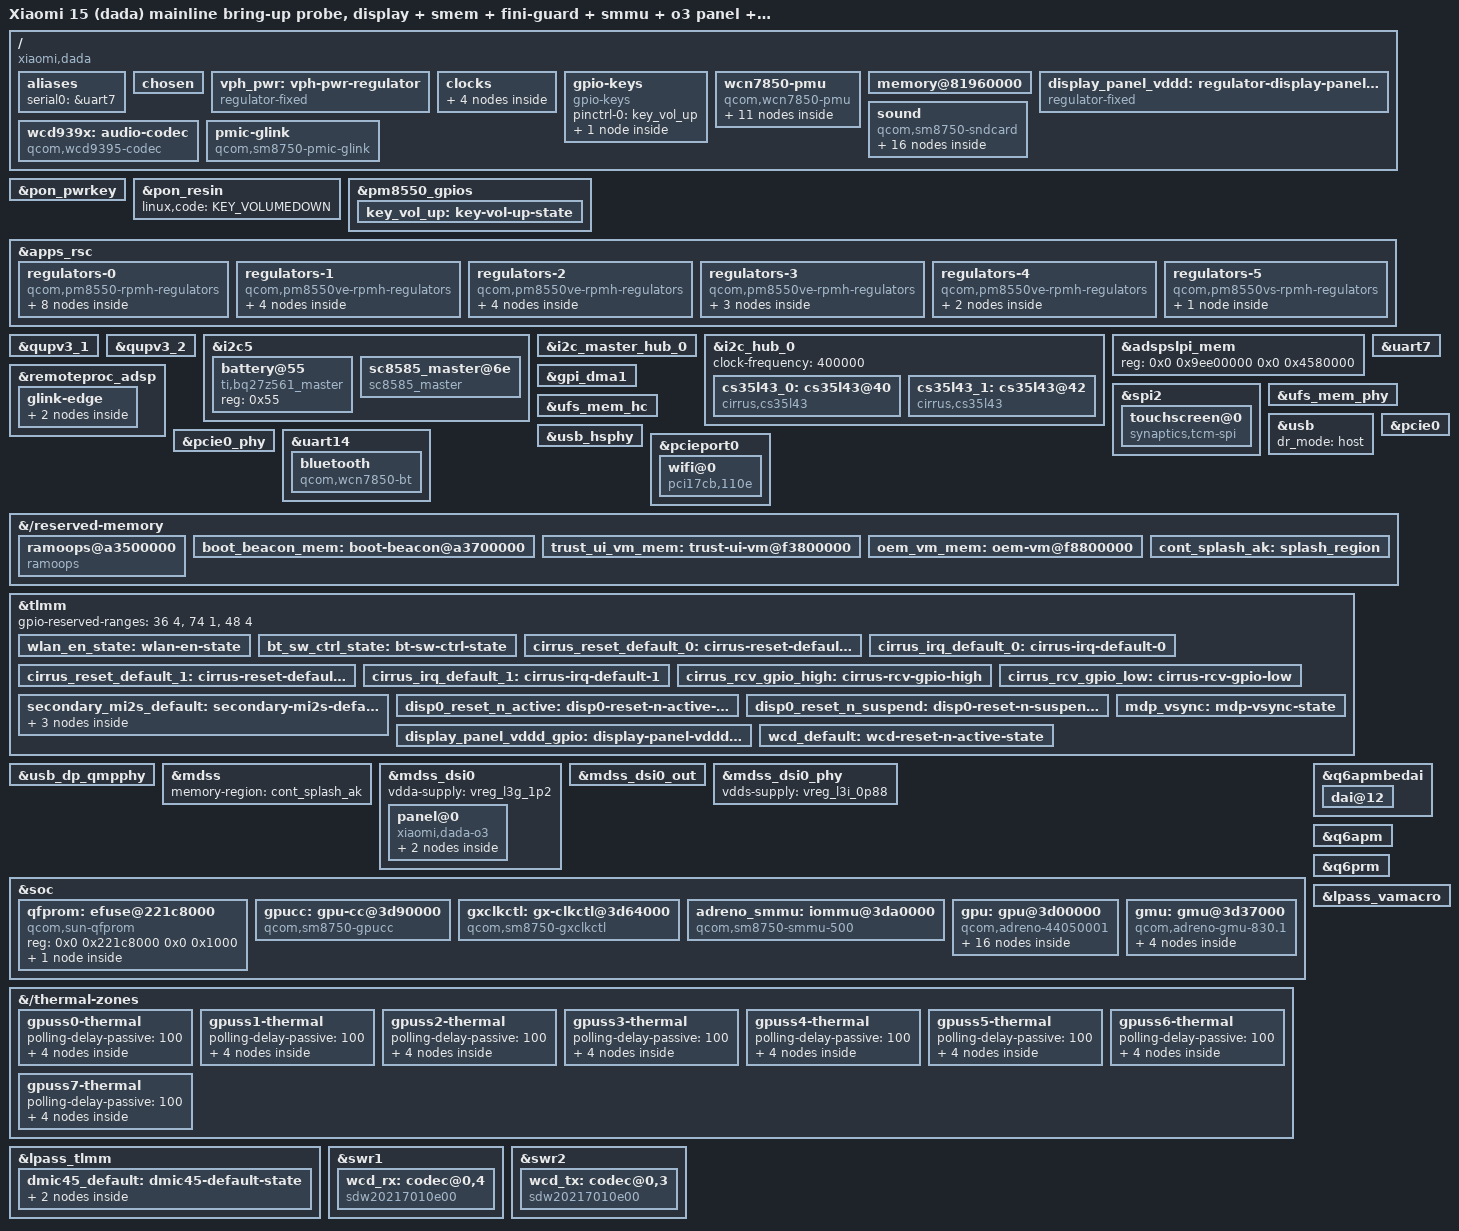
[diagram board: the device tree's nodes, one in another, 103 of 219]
// SPDX-License-Identifier: BSD-3-Clause
/*
 * Xiaomi 15 (dada) mainline bring-up board description -- CONSOLIDATED.
 *
 * This single file replaces the 66-file sm8750-xiaomi-dada-probe-*.dts include
 * chain (rounds m..cb) that had grown one thin override layer per bring-up
 * round. It was produced by work/kernel-source/scripts/merge-dts-chain.sh, which
 * walks the #include chain and inlines every board-level layer while KEEPING the
 * SoC and PMIC includes (sm8750.dtsi, the pm*.dtsi files, dt-bindings) as real
 * #include lines, so board-level picks of upstream DT changes still work.
 *
 * CORRECTNESS. The merge was verified to compile to a DTB that is BYTE-IDENTICAL
 * to the kernel's own build of the original chain, for rounds by, bz, ca and cb.
 * Nothing was dropped; the full round history lives in git (work/patches/round-*).
 *
 * WHY. The chain cost one DTS file + one Makefile dtb entry per round, so
 * `make dtbs` built 66 device trees for one board, and every new round meant
 * copying a file and wiring two more places. The rounds differed almost entirely
 * in /chosen bootargs; only ~10 of the 66 added real DT nodes.
 *
 * ROUND IDENTITY now lives in the `dada_probe=` cmdline token alone, not in the
 * filename. The current bootargs are the round-cb (SMP) set, with the probe tag
 * renamed builtin-dtb-cb -> builtin-dtb-mainline.
 *
 * HISTORY (oldest first): base board/PMIC/UFS/USB -> display bring-up probes
 * (m..aw: DPU/DSI enable, DSC, link config, readback, backlight, vendor table)
 * -> splash handover + SMMU direct-map (ax..bn) -> loopback rootfs -> pivot to
 * the rescue rootfs (bo) -> no-embedded-rootfs + dsi_host restored to BL (bp..bx)
 * -> persistent-rescue pivot + console prep (by) -> TSENS (bz) -> timing-robust
 * splash handover (ca) -> SMP, all 8 Oryon cores (cb).
 *
 * SECURITY: fastboot boot only, never flash; no partition written, erased or
 * made active; GPT never modified; read-only end to end except the one
 * pre-approved rescue-partition file, which the pivot rounds do not write
 * (round BO already seeded it). Per-run go-ahead required before any on-device
 * boot.
 *
 * Copyright (c) 2026 Xiaomi 15 mainline adaptation project
 */

/dts-v1/;

// SPDX-License-Identifier: BSD-3-Clause
/*
 * Xiaomi 15 (dada) initial mainline board description.
 *
 * This is deliberately a bring-up DTS.  Peripheral nodes are enabled only
 * after their vendor DT data has been mapped to mainline bindings.
 */


#include <dt-bindings/gpio/gpio.h>
#include <dt-bindings/input/input.h>
#include <dt-bindings/regulator/qcom,rpmh-regulator.h>
#include <dt-bindings/clock/qcom,sm8750-gpucc.h>
#include <dt-bindings/clock/qcom,kaanapali-gxclkctl.h>
#include <dt-bindings/sound/qcom,q6dsp-lpass-ports.h>
#include "sm8750.dtsi"
#include "pm8010.dtsi"
#include "pm8550.dtsi"
#define PMK8550VE_SID 8
#include "pm8550ve.dtsi"
#include "pmd8028.dtsi"
#include "pmih0108.dtsi"
#include "pmk8550.dtsi"
#include "pmr735d_a.dtsi"
#include "sm8750-pmics.dtsi"

/ {
	model = "Xiaomi 15";
	compatible = "xiaomi,dada", "qcom,sm8750";
	chassis-type = "handset";

	aliases {
		serial0 = &uart7;
	};

	chosen {
		stdout-path = "serial0:115200n8";
	};

	vph_pwr: vph-pwr-regulator {
		compatible = "regulator-fixed";

		regulator-name = "vph_pwr";
		regulator-min-microvolt = <3700000>;
		regulator-max-microvolt = <3700000>;

		regulator-always-on;
		regulator-boot-on;
	};

	clocks {
		xo_board: xo-board {
			compatible = "fixed-clock";
			clock-frequency = <76800000>;
			#clock-cells = <0>;
		};

		sleep_clk: sleep-clk {
			compatible = "fixed-clock";
			clock-frequency = <32000>;
			#clock-cells = <0>;
		};

		bi_tcxo_div2: bi-tcxo-div2-clk {
			compatible = "fixed-factor-clock";
			#clock-cells = <0>;

			clocks = <&rpmhcc RPMH_CXO_CLK>;
			clock-mult = <1>;
			clock-div = <2>;
		};

		bi_tcxo_ao_div2: bi-tcxo-ao-div2-clk {
			compatible = "fixed-factor-clock";
			#clock-cells = <0>;

			clocks = <&rpmhcc RPMH_CXO_CLK_A>;
			clock-mult = <1>;
			clock-div = <2>;
		};
	};
};

&pon_pwrkey {
	status = "okay";
};

&pon_resin {
	linux,code = <KEY_VOLUMEDOWN>;
	status = "okay";
};

/*
 * 音量加键不是 PON 键（电源键走 &pon_pwrkey，音量减走 &pon_resin）：
 * stock DT（android.dts fragment@3/@20）把它挂在 PM8550 PMIC GPIO6 上，
 * 由 gpio-keys 驱动处理 —— pinctrl input-enable + bias-pull-up +
 * power-source 1（1.8V），gpios active-low，linux,code=KEY_VOLUMEUP(0x73)，
 * gpio-key,wakeup，debounce 15ms。此前主线 DTS 缺这两个节点 ⇒ 音量加失效。
 */
&pm8550_gpios {
	key_vol_up: key-vol-up-state {
		pins = "gpio6";
		function = "normal";
		input-enable;
		bias-pull-up;
		power-source = <1>;
	};
};

/ {
	gpio-keys {
		compatible = "gpio-keys";

		pinctrl-names = "default";
		pinctrl-0 = <&key_vol_up>;

		vol_up {
			label = "volume_up";
			gpios = <&pm8550_gpios 6 GPIO_ACTIVE_LOW>;
			linux,input-type = <EV_KEY>;
			linux,code = <KEY_VOLUMEUP>;
			gpio-key,wakeup;
			debounce-interval = <15>;
		};
	};
};

&apps_rsc {
	regulators-0 {
		compatible = "qcom,pm8550-rpmh-regulators";

		vdd-bob1-supply = <&vph_pwr>;
		vdd-bob2-supply = <&vph_pwr>;
		vdd-l15-supply = <&vreg_s3g_1p8>;
		vdd-l17-supply = <&vreg_bob2>;

		qcom,pmic-id = "b";

		vreg_bob1: bob1 {
			regulator-name = "vreg_bob1";
			regulator-min-microvolt = <3008000>;
			regulator-max-microvolt = <4000000>;
			regulator-initial-mode = <RPMH_REGULATOR_MODE_HPM>;
		};

		vreg_bob2: bob2 {
			regulator-name = "vreg_bob2";
			regulator-min-microvolt = <2704000>;
			regulator-max-microvolt = <3008000>;
			regulator-initial-mode = <RPMH_REGULATOR_MODE_HPM>;
		};

		vreg_l17b_2p5: ldo17 {
			regulator-name = "vreg_l17b_2p5";
			regulator-min-microvolt = <2504000>;
			regulator-max-microvolt = <2504000>;
			regulator-initial-mode = <RPMH_REGULATOR_MODE_HPM>;
			regulator-allow-set-load;
			regulator-allowed-modes = <RPMH_REGULATOR_MODE_LPM
						   RPMH_REGULATOR_MODE_HPM>;
		};

		vreg_l15b_1p8: ldo15 {
			regulator-name = "vreg_l15b_1p8";
			regulator-min-microvolt = <1800000>;
			regulator-max-microvolt = <1800000>;
			regulator-initial-mode = <RPMH_REGULATOR_MODE_HPM>;
			regulator-allow-set-load;
			regulator-allowed-modes = <RPMH_REGULATOR_MODE_LPM
						   RPMH_REGULATOR_MODE_HPM>;
		};
	};

	regulators-1 {
		compatible = "qcom,pm8550ve-rpmh-regulators";

		vdd-l1-supply = <&vreg_s7i_1p2>;
		vdd-l2-supply = <&vreg_s1d_0p97>;
		vdd-l3-supply = <&vreg_s1d_0p97>;
		vdd-s1-supply = <&vph_pwr>;
		vdd-s3-supply = <&vph_pwr>;
		vdd-s4-supply = <&vph_pwr>;

		qcom,pmic-id = "d";

		vreg_s1d_0p97: smps1 {
			regulator-name = "vreg_s1d_0p97";
			regulator-min-microvolt = <880000>;
			regulator-max-microvolt = <1100000>;
			regulator-initial-mode = <RPMH_REGULATOR_MODE_HPM>;
		};

		vreg_s4d_0p85: smps4 {
			regulator-name = "vreg_s4d_0p85";
			regulator-min-microvolt = <500000>;
			regulator-max-microvolt = <1036000>;
			regulator-initial-mode = <RPMH_REGULATOR_MODE_HPM>;
		};

		vreg_l1d_1p2: ldo1 {
			regulator-name = "vreg_l1d_1p2";
			regulator-min-microvolt = <1200000>;
			regulator-max-microvolt = <1200000>;
			regulator-initial-mode = <RPMH_REGULATOR_MODE_HPM>;
			regulator-allow-set-load;
			regulator-allowed-modes = <RPMH_REGULATOR_MODE_LPM
						   RPMH_REGULATOR_MODE_HPM>;
		};
	};

	regulators-2 {
		compatible = "qcom,pm8550ve-rpmh-regulators";

		vdd-l1-supply = <&vreg_s1d_0p97>;
		vdd-l2-supply = <&vreg_s7i_1p2>;
		vdd-l3-supply = <&vreg_s3g_1p8>;
		vdd-s5-supply = <&vph_pwr>;

		qcom,pmic-id = "f";

		vreg_s5f_0p85: smps5 {
			regulator-name = "vreg_s5f_0p85";
			regulator-min-microvolt = <500000>;
			regulator-max-microvolt = <1000000>;
			regulator-initial-mode = <RPMH_REGULATOR_MODE_HPM>;
		};

		vreg_l1f_0p88: ldo1 {
			regulator-name = "vreg_l1f_0p88";
			regulator-min-microvolt = <880000>;
			regulator-max-microvolt = <880000>;
			regulator-initial-mode = <RPMH_REGULATOR_MODE_HPM>;
			regulator-allow-set-load;
			regulator-allowed-modes = <RPMH_REGULATOR_MODE_LPM
						   RPMH_REGULATOR_MODE_HPM>;
		};

		vreg_l2f_1p2: ldo2 {
			regulator-name = "vreg_l2f_1p2";
			regulator-min-microvolt = <1200000>;
			regulator-max-microvolt = <1200000>;
			regulator-initial-mode = <RPMH_REGULATOR_MODE_HPM>;
			regulator-allow-set-load;
			regulator-allowed-modes = <RPMH_REGULATOR_MODE_LPM
						   RPMH_REGULATOR_MODE_HPM>;
		};

		vreg_l3f_1p8: ldo3 {
			regulator-name = "vreg_l3f_1p8";
			regulator-min-microvolt = <1800000>;
			regulator-max-microvolt = <1800000>;
			regulator-initial-mode = <RPMH_REGULATOR_MODE_HPM>;
			regulator-allow-set-load;
			regulator-allowed-modes = <RPMH_REGULATOR_MODE_LPM
						   RPMH_REGULATOR_MODE_HPM>;
		};
	};

	regulators-3 {
		compatible = "qcom,pm8550ve-rpmh-regulators";

		vdd-l1-supply = <&vreg_s1d_0p97>;
		vdd-l2-supply = <&vreg_s3g_1p8>;
		vdd-l3-supply = <&vreg_s7i_1p2>;
		vdd-s1-supply = <&vph_pwr>;
		vdd-s3-supply = <&vph_pwr>;

		qcom,pmic-id = "g";

		vreg_s3g_1p8: smps3 {
			regulator-name = "vreg_s3g_1p8";
			regulator-min-microvolt = <1856000>;
			regulator-max-microvolt = <2000000>;
			regulator-initial-mode = <RPMH_REGULATOR_MODE_LPM>;
		};

		vreg_l3g_1p2: ldo3 {
			regulator-name = "vreg_l3g_1p2";
			regulator-min-microvolt = <1200000>;
			regulator-max-microvolt = <1256000>;
			regulator-initial-mode = <RPMH_REGULATOR_MODE_HPM>;
			regulator-allow-set-load;
			regulator-allowed-modes = <RPMH_REGULATOR_MODE_LPM
						   RPMH_REGULATOR_MODE_HPM>;
		};
	};

	regulators-4 {
		compatible = "qcom,pm8550ve-rpmh-regulators";

		vdd-l1-supply = <&vreg_s7i_1p2>;
		vdd-l2-supply = <&vreg_s7i_1p2>;
		vdd-l3-supply = <&vreg_s1d_0p97>;
		vdd-s7-supply = <&vph_pwr>;
		vdd-s8-supply = <&vph_pwr>;

		qcom,pmic-id = "i";

		vreg_s7i_1p2: smps7 {
			regulator-name = "vreg_s7i_1p2";
			regulator-min-microvolt = <1224000>;
			regulator-max-microvolt = <1340000>;
			regulator-initial-mode = <RPMH_REGULATOR_MODE_HPM>;
		};

		vreg_l2i_1p2: ldo2 {
			regulator-name = "vreg_l2i_1p2";
			regulator-min-microvolt = <1200000>;
			regulator-max-microvolt = <1200000>;
			regulator-initial-mode = <RPMH_REGULATOR_MODE_HPM>;
			regulator-allow-set-load;
			regulator-allowed-modes = <RPMH_REGULATOR_MODE_LPM
						   RPMH_REGULATOR_MODE_HPM>;
		};
	};

	regulators-5 {
		compatible = "qcom,pm8550vs-rpmh-regulators";

		vdd-l1-supply = <&vreg_s1d_0p97>;
		vdd-l2-supply = <&vreg_s7i_1p2>;
		vdd-s2-supply = <&vph_pwr>;
		vdd-s3-supply = <&vph_pwr>;
		vdd-s4-supply = <&vph_pwr>;

		qcom,pmic-id = "j";

		vreg_l1j_0p91: ldo1 {
			regulator-name = "vreg_l1j_0p91";
			regulator-min-microvolt = <880000>;
			regulator-max-microvolt = <920000>;
			regulator-initial-mode = <RPMH_REGULATOR_MODE_HPM>;
			regulator-allow-set-load;
			regulator-allowed-modes = <RPMH_REGULATOR_MODE_LPM
						   RPMH_REGULATOR_MODE_HPM>;
		};
	};
};

&qupv3_1 {
	status = "okay";
};

&qupv3_2 {
	status = "okay";
};

/*
 * Battery fuel gauge (2026-09-30).
 *
 * dada's battery data does NOT come from the ADSP: the stock DT keeps the
 * APSS-side pmic_glink battery clients disabled (/soc/qcom,pmic_glink/
 * qcom,battery_charger and mca,adsp_glink are both "disabled"), and once the
 * ADSP remoteproc is up the charger_pd service still answers every battmgr
 * property request with {0, 1, <property echoed>, 0} + 252 zero bytes.
 *
 * The real source is a TI bq27z561 fuel gauge on QUPv3_1 SE5 (i2c@a94000,
 * SDA gpio52 / SCL gpio53, address 0x55), which the stock DT keeps enabled
 * as ti,bq27z561_master.  Mainline's bq27xxx driver knows plain
 * ti,bq27z561: no unseal and no "master" mode is needed.  Verified on
 * hardware -- capacity 85 %, Discharging, 4.245 V, -361 mA, 38.9 C, 575
 * cycles, charge_full 4954 mAh / design 5400 mAh.  The design capacity comes
 * from the gauge's DCAP register, not from the stock DT's
 * bq,charge-full-design = 5300 mAh.
 *
 * Deliberately no monitored-battery child: bq27xxx_battery_settings() is its
 * only consumer and for BQ27Z561 (dm_regs == NULL) it bails out with "data
 * memory update not supported for chip", so it would only add a boot warning.
 */
&i2c5 {
	status = "okay";

	battery@55 {
		compatible = "ti,bq27z561_master";
		reg = <0x55>;
	};
};

/*
 * 扬声器：双 Cirrus CS35L43 挂在 I2C master hub 0（stock DTBO fragment@93
 * 的 target = qupv3_hub_i2c0 → 主线 i2c@980000，见 docs/audio-fix.md「硬件事实」2）。
 *
 * 两级都必须开：i2c_master_hub_0（父，geniqup@9c0000）在 sm8750.dtsi:1245
 * 与 i2c_hub_0 自身在 :1278 都是 status="disabled"。pad 沿用 dtsi 已有的
 * hub_i2c0_data_clk (gpio64/65)，无需另写 pinctrl。
 *
 * 风险：本文件上方注释记录过 i2c_hub_1 在传感器路线上 probe 死锁被放弃；
 * 功放走的是另一个 SE（hub 0），理论独立，但仍需上机验证。
 */
&i2c_master_hub_0 {
	status = "okay";
};

&i2c_hub_0 {
	status = "okay";

	/*
	 * dtsi 未给 clock-frequency，geni_i2c 会打 "Bus frequency not specified,
	 * default to 100kHz"（i2c-qcom-geni.c:1169-1173）。DSP 固件 .wmfw 里最大的
	 * PM_PACKED 区 19900 字节是单次 regmap_raw_write → 单条 I2C 事务，
	 * 100kHz 下约 1.79s，超过 geni_i2c 的 XFER_TIMEOUT=HZ（1s，i2c-qcom-geni.c:82）
	 * ⇒ cs_dsp.c:1676 "Failed to write 19900 bytes ...: -110"，固件加载中断。
	 * 400kHz 下约 0.45s；CS35L43 支持 fast mode。
	 */
	clock-frequency = <400000>;

	/* Bottom 主扬声器（stock phandle 0x26f，i2c-addr 0x28 → reg 0x40） */
	cs35l43_0: cs35l43@40 {
		compatible = "cirrus,cs35l43";
		reg = <0x40>;
		#sound-dai-cells = <0>;

		/*
		 * 一符三用：ASoC 的 DAPM widget / kcontrol 前缀（"B SPK"…），
		 * 以及 cs35l43_dsp_init 里 DSP 固件名的 part 前缀
		 * （"B-cs35l43" → wm_adsp.c:764 小写化 → cirrus/b-cs35l43-*.bin）。
		 * 取值必须与固件文件名的前缀一致，故用 "B"/"T" 而非 "Bottom"。
		 */
		sound-name-prefix = "B";

		interrupt-parent = <&tlmm>;
		interrupts = <84 0x2008>;
		reset-gpios = <&tlmm 107 GPIO_ACTIVE_HIGH>;

		pinctrl-names = "default";
		pinctrl-0 = <&cirrus_reset_default_0 &cirrus_irq_default_0>;

		/*
		 * 只写主线驱动 cs35l43_parse_pdata 实际读取的属性。
		 * stock 的 cirrus,vpbr-* / cirrus,bst-ipk-ma /
		 * cirrus,low-pwr-mode-standby 等主线一律不读，写了无用，
		 * 这里刻意省略（docs「架构结论」6）。
		 */
		cirrus,asp-sdout-hiz = <3>;
		cirrus,gpio2-src-sel = <4>;
	};

	/* Top 侧，兼作听筒（stock phandle 0x270，i2c-addr 0x2a → reg 0x42） */
	cs35l43_1: cs35l43@42 {
		compatible = "cirrus,cs35l43";
		reg = <0x42>;
		#sound-dai-cells = <0>;
		sound-name-prefix = "T";

		interrupt-parent = <&tlmm>;
		interrupts = <66 0x2008>;
		reset-gpios = <&tlmm 108 GPIO_ACTIVE_HIGH>;

		pinctrl-names = "default";
		pinctrl-0 = <&cirrus_reset_default_1 &cirrus_irq_default_1>;

		cirrus,asp-sdout-hiz = <3>;
		cirrus,gpio2-src-sel = <4>;
	};
};

/*
 * Sensor fix Phase 1: SSC path via ADSP remoteproc + FastRPC.
 *
 * The AP-side i2c-hub route (S1/A1/A2/B rounds) deadlocks in i2c_hub_1
 * probe and is abandoned; the same-SoC reference port (tb322fc Y700 Gen4,
 * Linux 7.2) validates accel/gyro/light through the SSC/ADSP instead.
 *
 * Stock dada DTB (extracted from vendor_boot_a.img) confirms the fastrpc
 * compute-cb iommus already match the upstream sm8750 base exactly
 * (cb@3 0x1003 0x80 + 0x1043 0x20; cb@7 0x1007 0x40 + 0x1067 0x00 +
 * 0x1087 0x00), so NO iommus override is needed -- unlike Y700, which
 * rewrites them. Only the PAS firmware names, enable, and stock's
 * nsessions on compute-cb@4 are added here.
 *
 * Firmware target on rootfs: /lib/firmware/qcom/sm8750/adsp.mdt (+ segments)
 * and adsp_dtb.mdt (+ segments), copied from the stock Android vendor image.
 *
 * Reserved-memory sizing: stock dada DTB reserves 0x4580000 for
 * adspslpi_region@9ee00000 while the mainline base only carves 0x3a80000.
 * The stock adsp.mdt is a relocatable ELF whose loadable segment span is
 * exactly 0x4580000 (0x9f300000..0xa3880000), so mainline's smaller window
 * fails qcom_mdt_load() with "segment outside memory range" (-22).  The
 * next real reserved node upstream is xbl-ramdump@b8000000, so growing the
 * region to the stock size collides with nothing.
 */
&adspslpi_mem {
	reg = <0x0 0x9ee00000 0x0 0x4580000>;
};

&remoteproc_adsp {
	firmware-name = "qcom/sm8750/adsp.mdt",
			"qcom/sm8750/adsp_dtb.mdt";
	status = "okay";

	glink-edge {
		fastrpc {
			compute-cb@4 {
				qcom,nsessions = <8>;
			};
		};
	};
};

&uart7 {
	status = "okay";
};

/*
 * Touch Round CM (SPI foundation). The touch IC -- Synaptics S3910P,
 * TouchComm over SPI, compatible "synaptics,tcm-spi" -- hangs off spi2
 * (QUPv3_1 SE2: irq TLMM gpio162 level-low+wakeup, reset gpio161, CS0
 * 15 MHz mode 0, per the stock runtime DT). The SoC dtsi carries the full
 * master node (pinctrl qup_spi2_data_clk/cs, GCC_QUPV3_WRAP1_S2_CLK,
 * interconnects, gpi_dma1 tx/rx channels) disabled, and its DMA engine
 * gpi_dma1 likewise; spi-geni probe defers forever if the SE comes up
 * GPI-only without it. Enable both here.
 * Inert while CONFIG_SPI_QCOM_GENI is off (no driver binds the node).
 *
 * Touch Round CN (TCM driver). The touch child node lands here, carrying
 * exactly the stock vendor properties (runtime.dts 24864-24940): irq gpio162
 * level-low, reset gpio161 active-high, 15 MHz SPI mode 0, avdd/iovdd named
 * supplies resolved to the pm8550 ("b" die) rails that own ldob16/ldob12 in
 * the stock DT (pm_humu_l16 = 3.0 V fixed avdd per the authoritative
 * runtime DT; pm_humu_l12 = 1.8 V iovdd), the panel geometry (1200x2670, tx 38 / rx 17) and the stock firmware image
 * name. Deliberately NOT ported: mi_tp,* arrays, qts/trusted-touch-*,
 * syna,qts_en, FOD arrays, xiaomi_touch (vendor framework glue).
 * The TCM driver reads its geometry from the IC app info; max-x/max-y/
 * tx-num/rx-num are kept for documentation parity with the stock DT.
 */
&gpi_dma1 {
	status = "okay";
};

&spi2 {
	status = "okay";

	touchscreen@0 {
		compatible = "synaptics,tcm-spi";
		reg = <0>;
		spi-max-frequency = <15000000>;
		synaptics,spi-mode = <0>;
		interrupt-parent = <&tlmm>;
		interrupts = <162 IRQ_TYPE_LEVEL_LOW>;
		synaptics,irq-gpio = <&tlmm 162 GPIO_ACTIVE_LOW>;
		synaptics,irq-on-state = <0>;
		synaptics,reset-gpio = <&tlmm 161 GPIO_ACTIVE_HIGH>;
		synaptics,reset-active-ms = <10>;
		synaptics,reset-delay-ms = <200>;
		synaptics,power-delay-ms = <50>;
		synaptics,avdd-name = "avdd";
		avdd-supply = <&vreg_l16b_3p0>;
		synaptics,iovdd-name = "iovdd";
		iovdd-supply = <&vreg_l12b_1p8>;
		synaptics,max-x = <1200>;
		synaptics,max-y = <2670>;
		synaptics,tx-num = <38>;
		synaptics,rx-num = <17>;
		synaptics,default-fw-image-name = "synaptics_spi_dada_00.img";
	};
};

/* Required for the first storage and USB bring-up pass. */
&ufs_mem_phy {
	vdda-phy-supply = <&vreg_l1j_0p91>;
	vdda-pll-supply = <&vreg_l3g_1p2>;

	status = "okay";
};

&ufs_mem_hc {
	reset-gpios = <&tlmm 215 GPIO_ACTIVE_LOW>;

	vcc-supply = <&vreg_l17b_2p5>;
	vcc-max-microamp = <1300000>;
	vccq-supply = <&vreg_l1d_1p2>;
	vccq-max-microamp = <1200000>;

	status = "okay";
};

&usb {
	dr_mode = "host";
	/delete-property/ usb-role-switch;
	status = "okay";
};

&usb_hsphy {
	status = "okay";
};

/* WiFi (WCN7850 "Peach") via PCIe. */
&pcie0 {
	vdda-supply = <&vreg_l1f_0p88>;
	pinctrl-0 = <&pcie0_default_state>;
	pinctrl-names = "default";
	status = "okay";
};

&pcie0_phy {
	vdda-phy-supply = <&vreg_l1f_0p88>;
	vdda-pll-supply = <&vreg_l3g_1p2>;
	status = "okay";
};

/ {
	wcn7850-pmu {
		compatible = "qcom,wcn7850-pmu";

		pinctrl-names = "default";
		pinctrl-0 = <&wlan_en_state>, <&bt_sw_ctrl_state>;

		wlan-enable-gpios = <&tlmm 16 GPIO_ACTIVE_HIGH>;
		bt-enable-gpios = <&pm8550ve_f_gpios 3 GPIO_ACTIVE_HIGH>;

		vdd-supply = <&vreg_s5f_0p85>;
		vddio-supply = <&vreg_l3f_1p8>;
		vddio1p2-supply = <&vreg_l2f_1p2>;
		vddaon-supply = <&vreg_s4d_0p85>;
		vdddig-supply = <&vreg_s5f_0p85>;
		vddrfa1p2-supply = <&vreg_s7i_1p2>;
		vddrfa1p8-supply = <&vreg_s3g_1p8>;

		clocks = <&rpmhcc RPMH_RF_CLK1>;

		regulators {
			vreg_pmu_rfa_cmn: ldo0 {
				regulator-name = "vreg_pmu_rfa_cmn";
			};

			vreg_pmu_aon_0p59: ldo1 {
				regulator-name = "vreg_pmu_aon_0p59";
			};

			vreg_pmu_wlcx_0p8: ldo2 {
				regulator-name = "vreg_pmu_wlcx_0p8";
			};

			vreg_pmu_wlmx_0p85: ldo3 {
				regulator-name = "vreg_pmu_wlmx_0p85";
			};

			vreg_pmu_btcmx_0p85: ldo4 {
				regulator-name = "vreg_pmu_btcmx_0p85";
			};

			vreg_pmu_rfa_0p8: ldo5 {
				regulator-name = "vreg_pmu_rfa_0p8";
			};

			vreg_pmu_rfa_1p2: ldo6 {
				regulator-name = "vreg_pmu_rfa_1p2";
			};

			vreg_pmu_rfa_1p8: ldo7 {
				regulator-name = "vreg_pmu_rfa_1p8";
			};

			vreg_pmu_pcie_0p9: ldo8 {
				regulator-name = "vreg_pmu_pcie_0p9";
			};

			vreg_pmu_pcie_1p8: ldo9 {
				regulator-name = "vreg_pmu_pcie_1p8";
			};
		};
	};
};

&uart14 {
	pinctrl-0 = <&qup_uart14_default>, <&qup_uart14_cts_rts>;

	status = "okay";

	/* WCN7880 (Peach, ganges) uses the WCN7850 UART protocol. */
	bluetooth {
		compatible = "qcom,wcn7850-bt";

		firmware-name = "gngbtnv20.bin", "gngbtfw20.mbn";
		/* Android-assigned public address 74:38:22:97:79:E5,
		 * stored little-endian in DT. */
		local-bd-address = [e5 79 97 22 38 74];

		vddrfacmn-supply = <&vreg_pmu_rfa_cmn>;
		vddaon-supply = <&vreg_pmu_aon_0p59>;
		vddwlcx-supply = <&vreg_pmu_wlcx_0p8>;
		vddwlmx-supply = <&vreg_pmu_wlmx_0p85>;
		vddrfa0p8-supply = <&vreg_pmu_rfa_0p8>;
		vddrfa1p2-supply = <&vreg_pmu_rfa_1p2>;
		vddrfa1p8-supply = <&vreg_pmu_rfa_1p8>;

		/* 主线 qca_get_baudrate_value() 无 8M case（default→115200 会
		 * 造成控制器留 115200、主机切 8M 的波特率错配），先按 MTP 用 3200000。 */
		max-speed = <3200000>;
	};
};

&pcieport0 {
	wake-gpios = <&tlmm 104 GPIO_ACTIVE_HIGH>;
	reset-gpios = <&tlmm 102 GPIO_ACTIVE_LOW>;

	wifi@0 {
		compatible = "pci17cb,110e";
		reg = <0x10000 0x0 0x0 0x0 0x0>;

		vddrfacmn-supply = <&vreg_pmu_rfa_cmn>;
		vddaon-supply = <&vreg_pmu_aon_0p59>;
		vddwlcx-supply = <&vreg_pmu_wlcx_0p8>;
		vddwlmx-supply = <&vreg_pmu_wlmx_0p85>;
		vddrfa0p8-supply = <&vreg_pmu_rfa_0p8>;
		vddrfa1p2-supply = <&vreg_pmu_rfa_1p2>;
		vddrfa1p8-supply = <&vreg_pmu_rfa_1p8>;
		vddpcie0p9-supply = <&vreg_pmu_pcie_0p9>;
		vddpcie1p8-supply = <&vreg_pmu_pcie_1p8>;
	};
};

/* The stock vendor DT reserves this area for crash/pstore records. */
&{/reserved-memory} {
	ramoops@a3500000 {
		compatible = "ramoops";
		reg = <0x0 0xa3500000 0x0 0x400000>;
		console-size = <0x200000>;
		pmsg-size = <0x200000>;
	};
};

/ {
	model = "Xiaomi 15 (dada) mainline bring-up probe";

	/*
	 * Verbatim from the ABL-populated /memory reg of the runtime device
	 * tree, sorted, with the single zero-length bank at 0xd8600000
	 * dropped. 15.12 GiB in 16 banks.
	 */
	memory@81960000 {
		device_type = "memory";
		reg = <0x00 0x81960000 0x00 0x000a0000>,
		      <0x00 0x81a40000 0x00 0x001c0000>,
		      <0x00 0x81cf4800 0x00 0x0000b800>,
		      <0x00 0x82460000 0x00 0x00040000>,
		      <0x00 0x82800000 0x00 0x02200000>,
		      <0x00 0x89d80000 0x00 0x01c80000>,
		      <0x00 0xa3380000 0x00 0x14c80000>,
		      <0x00 0xb8200000 0x00 0x1cc23000>,
		      <0x00 0xd5100000 0x00 0x02f00000>,
		      <0x00 0xe3720000 0x00 0x150e0000>,
		      <0x00 0xfc400000 0x00 0x03400000>,
		      <0x08 0x80000000 0x00 0x2f6fd000>,
		      <0x08 0xb0000000 0x00 0x05500000>,
		      <0x08 0xb5700000 0x00 0x01e00000>,
		      <0x08 0xc0000000 0x01 0x40000000>,
		      <0x0a 0x00000000 0x02 0x00000000>;
	};

	chosen {
		/*
		 * console=tty0 is intentional. The board has no accessible
		 * UART, and /chosen stdout-path would otherwise make the geni
		 * driver take over as the console; a console write that stalls
		 * on a port nobody is listening to would destroy the only
		 * evidence channel this probe has. Setting any console= on the
		 * command line makes of_console_check() ignore stdout-path,
		 * which is also what the stock kernel does.
		 *
		 * The pstore console does not need to be named here: it forces
		 * CON_ENABLED | CON_PRINTBUFFER | CON_ANYTIME at registration,
		 * so it is enabled anyway and replays the whole log buffer.
		 *
		 * clk/pd/regulator_ignore_unused keeps the late_initcall sync
		 * from switching off resources that firmware still owns.
		 *
		 * maxcpus=1 keeps secondary CPU bring-up out of the picture for
		 * the first probe.
		 *
		 * printk.devkmsg=on is required, not cosmetic. The default is
		 * ratelimit = 10 messages per 5 s per open fd, and round K lost
		 * exactly 6 of dada-init's lines to it (see
		 * evidence/probe-run-k-2026-09-06.md section 5.6).
		 *
		 * dada_probe= is only a self-identifying tag. Note it comes from
		 * HERE and not from the boot image header for this variant: the
		 * bootloader FDT is discarded, so /chosen in this blob is the
		 * only cmdline the kernel sees. Round K shipped with the stale
		 * "builtin-dtb-c" tag for that reason.
		 */
		bootargs = "console=tty0 ignore_loglevel nokaslr clk_ignore_unused pd_ignore_unused regulator_ignore_unused panic=5 printk.devkmsg=on rdinit=/dada-init dada_probe=builtin-dtb-gpu root=/dev/sda36 rw rootwait loglevel=4 systemd.show_status=yes ath12k.mac_addr=CE:76:4A:AB:26:35 root=/dev/sda36 rw rootwait loglevel=4 systemd.show_status=yes";
	};
};

&{/reserved-memory} {
	/*
	 * Two independent evidence channels, on two non-overlapping zones.
	 *
	 * Android declares ramoops at 0xa3500000 size 0x400000 with console-size
	 * and pmsg-size both 0x200000, and no record-size or ftrace-size. The
	 * mainline split order in ramoops_probe() is dmesg -> console -> ftrace
	 * -> pmsg, and dmesg and ftrace are both zero bytes here, so Android's
	 * console zone is 0xa3500000 and its pmsg zone is 0xa3700000.
	 *
	 * 0xa3700000 belongs to arm64_boot_beacon() alone. It is the reliable
	 * channel: it writes from inside setup_arch(), does explicit cache
	 * maintenance to the point of coherency, and never advances start, so its
	 * header satisfies start <= size at every instant. It reads back as
	 * /sys/fs/pstore/pmsg-ramoops-0.
	 *
	 * 0xa3500000 holds this kernel's own pstore_ram console zone, which only
	 * works if the kernel survives to driver init but then carries the whole
	 * replayed log. It reads back as /sys/fs/pstore/console-ramoops-0.
	 *
	 * These two must not share a zone. On 2026-09-05 both were pointed at
	 * 0xa3700000 and the resulting torn header cost the entire round: see
	 * plan section 13.13 and 13.14.
	 *
	 * CONFIG_ARM64_BOOT_BEACON_ADDR must stay 0xa3700000.
	 */
	/delete-node/ ramoops@a3500000;

	ramoops@a3500000 {
		compatible = "ramoops";
		reg = <0x00 0xa3500000 0x00 0x200000>;
		console-size = <0x200000>;
	};

	/*
	 * The beacon zone. Deliberately not a ramoops node: this kernel writes
	 * it by hand from setup_arch() onward and must not also have pstore_ram
	 * bookkeeping on it. It is reserved only to keep the page allocator out,
	 * which round D needs because its call sites now run past mm_core_init().
	 * Must match CONFIG_ARM64_BOOT_BEACON_ADDR / _SIZE.
	 */
	boot_beacon_mem: boot-beacon@a3700000 {
		reg = <0x00 0xa3700000 0x00 0x200000>;
		no-map;
	};

	/*
	 * Round K found "OF: reserved mem: OVERLAP DETECTED!" here. Upstream
	 * sm8750.dtsi and the dada runtime device tree disagree about both of
	 * these nodes, and this overlay had only followed the runtime tree for
	 * the first one:
	 *
	 *                   runtime (authoritative for dada)   sm8750.dtsi
	 *   trust-ui-vm     0xf3800000 + 0x5000000 (80M)       + 0x4400000 (68M)
	 *   oem-vm          0xf8800000 + 0x3800000 (56M)       0xf7c00000
	 *                                                      + 0x4c00000 (76M)
	 *
	 * Widening trust-ui-vm to the runtime size without also moving oem-vm
	 * left 0xf7c00000..0xf87fffff claimed twice. Both are no-map, so
	 * __rmem_check_for_overlap() only warned and round K was unharmed, but
	 * the probe tree is supposed to mirror the real memory map, so follow
	 * the runtime tree for both. Note the runtime node names are
	 * trust_ui_vm_region@/oem_vm_region@; keep the upstream node names so
	 * this stays a size/address correction and not a rename.
	 */
	trust_ui_vm_mem: trust-ui-vm@f3800000 {
		reg = <0x00 0xf3800000 0x00 0x5000000>;
		no-map;
	};

	/delete-node/ oem-vm@f7c00000;

	oem_vm_mem: oem-vm@f8800000 {
		reg = <0x00 0xf8800000 0x00 0x3800000>;
		no-map;
	};

	cont_splash_mem: cont-splash@fc800000 {
		reg = <0x00 0xfc800000 0x00 0x2b00000>;
		no-map;
	};
};

/ {
	model = "Xiaomi 15 (dada) mainline bring-up probe, pdc enabled";

	chosen {
		/*
		 * Byte-for-byte round L's command line with the tag changed. If
		 * this boot behaves differently from round L, CONFIG_QCOM_PDC=y
		 * has to be the only reason it can.
		 */
		bootargs = "console=tty0 ignore_loglevel nokaslr maxcpus=1 clk_ignore_unused pd_ignore_unused regulator_ignore_unused panic=5 printk.devkmsg=on rdinit=/dada-init dada_probe=builtin-dtb-gpu root=/dev/sda36 rw rootwait loglevel=4 systemd.show_status=yes ath12k.mac_addr=CE:76:4A:AB:26:35 root=/dev/sda36 rw rootwait loglevel=4 systemd.show_status=yes";
	};
};

/ {
	model = "Xiaomi 15 (dada) mainline bring-up probe, pdc + tlmm reserved";

	chosen {
		bootargs = "console=tty0 ignore_loglevel nokaslr maxcpus=1 clk_ignore_unused pd_ignore_unused regulator_ignore_unused panic=5 printk.devkmsg=on rdinit=/dada-init dada_probe=builtin-dtb-gpu root=/dev/sda36 rw rootwait loglevel=4 systemd.show_status=yes ath12k.mac_addr=CE:76:4A:AB:26:35 root=/dev/sda36 rw rootwait loglevel=4 systemd.show_status=yes";
	};
};

&tlmm {
	/*
	 * The single variable. See the header comment for why these three
	 * ranges and nothing else.
	 */
	gpio-reserved-ranges = <36 4>, <74 1>, <48 4>;

	wlan_en_state: wlan-en-state {
		pins = "gpio16";
		function = "gpio";
		drive-strength = <4>;
		bias-pull-down;
		output-low;
	};

	/* BT sw-ctrl (stock qcom,bt-sw-ctrl-gpio = tlmm 18), per sm8750-mtp. */
	bt_sw_ctrl_state: bt-sw-ctrl-state {
		pins = "gpio18";
		function = "gpio";
		bias-pull-down;
	};

	/*
	 * ── 音频：双 Cirrus CS35L43 + LPASS 第二接口（I2S/MI2S）──
	 * 见 docs/audio-fix.md「硬件事实」1/3。gpio 号全部来自 stock DTBO
	 * fragment@93 / :19244，且在本文件中无任何其它占用（已逐一核对）。
	 */

	/* amp@40 (Bottom, i2c 0x40)：reset=gpio107  irq=gpio84 */
	cirrus_reset_default_0: cirrus-reset-default-0 {
		pins = "gpio107";
		function = "gpio";
		drive-strength = <2>;
		bias-pull-up;
		output-high;
	};

	cirrus_irq_default_0: cirrus-irq-default-0 {
		pins = "gpio84";
		function = "gpio";
		drive-strength = <2>;
		bias-pull-up;
		input-enable;
	};

	/* amp@42 (Top, i2c 0x42)：reset=gpio108  irq=gpio66 */
	cirrus_reset_default_1: cirrus-reset-default-1 {
		pins = "gpio108";
		function = "gpio";
		drive-strength = <2>;
		bias-pull-up;
		output-high;
	};

	cirrus_irq_default_1: cirrus-irq-default-1 {
		pins = "gpio66";
		function = "gpio";
		drive-strength = <2>;
		bias-pull-up;
		input-enable;
	};

	/*
	 * amp@42 的听筒 rcv 脚（stock pinctrl-names 为 rcv_gpio_high/low，
	 * gpio152/gpio67）。方向与电平未知，第一阶段不挂到 amp 的 pinctrl-0，
	 * 仅预留 group 定义以免后续占用冲突。
	 */
	cirrus_rcv_gpio_high: cirrus-rcv-gpio-high {
		pins = "gpio152";
		function = "gpio";
		drive-strength = <2>;
		bias-pull-up;
		output-low;
	};

	cirrus_rcv_gpio_low: cirrus-rcv-gpio-low {
		pins = "gpio67";
		function = "gpio";
		drive-strength = <2>;
		bias-pull-up;
		output-low;
	};

	/*
	 * LPASS 第二接口的 pad（gpio121/123/124）。四个 function 各不相同，
	 * 故用嵌套 sub-group（同 lpass_tlmm 的 tx_swr_active 写法）。
	 * 逐字照抄已验证出声的 sm8750-lenovo-elden.dts:2091
	 * secondary_mi2s_default —— 不含 gpio122(din)，因为 I2S 播放单向，
	 * 且 CS35L43 的 IMON/VMON 走片内 ADC 不经外部 din。
	 * stock 的 aud_sleep state 也暂不建（elden 同样没有）。
	 */
	secondary_mi2s_default: secondary-mi2s-default-state {
		clock-pins {
			pins = "gpio121";
			function = "i2s1_sck";
			drive-strength = <8>;
			bias-disable;
		};
		word-select-pins {
			pins = "gpio123";
			function = "i2s1_ws";
			drive-strength = <8>;
			bias-disable;
		};
		data-pins {
			pins = "gpio124";
			function = "i2s1_data1";
			drive-strength = <8>;
			bias-disable;
		};
	};
};

/ {
	model = "Xiaomi 15 (dada) mainline bring-up probe, pdc + tlmm reserved + rpmh unblocked";

	chosen {
		/*
		 * Byte-for-byte the round P command line with the tag changed.
		 * If this boot behaves differently from round P, the deleted
		 * power-domains property has to be the only reason it can.
		 */
		bootargs = "console=tty0 ignore_loglevel nokaslr maxcpus=1 clk_ignore_unused pd_ignore_unused regulator_ignore_unused panic=5 printk.devkmsg=on rdinit=/dada-init dada_probe=builtin-dtb-gpu root=/dev/sda36 rw rootwait loglevel=4 systemd.show_status=yes ath12k.mac_addr=CE:76:4A:AB:26:35 root=/dev/sda36 rw rootwait loglevel=4 systemd.show_status=yes";
	};
};

&apps_rsc {
	/*
	 * The one line this file adds on top of round P. Round M's proven
	 * variable, verbatim from sm8750-xiaomi-dada-probe-m.dts.
	 *
	 * /delete-property/ and not a status change: apps_rsc must still probe,
	 * it must just stop waiting for a supplier that can never appear
	 * (/psci/power-domain-system never becomes a struct device because
	 * of_platform_default_populate() does not recurse into arm,psci-1.0
	 * and CONFIG_ARM_PSCI_CPUIDLE_DOMAIN is off in this kernel).
	 */
	/delete-property/ power-domains;
};

/ {
	model = "Xiaomi 15 (dada) mainline bring-up probe, pdc + tlmm + rpmh + g_serial";

	chosen {
		/*
		 * The Q command line plus console=ttyGS0,115200. ttynull
		 * stays as the early console (g_serial is not up until
		 * initcall time); once g_serial binds, the console switches.
		 * This is the standard two-stage console pattern for USB
		 * gadget consoles.
		 */
		bootargs = "console=tty0 ignore_loglevel nokaslr maxcpus=1 clk_ignore_unused pd_ignore_unused regulator_ignore_unused panic=5 printk.devkmsg=on rdinit=/dada-init dada_probe=builtin-dtb-gpu root=/dev/sda36 rw rootwait loglevel=4 systemd.show_status=yes ath12k.mac_addr=CE:76:4A:AB:26:35 root=/dev/sda36 rw rootwait loglevel=4 systemd.show_status=yes";
	};
};

/ {
	model = "Xiaomi 15 (dada) mainline bring-up probe, pdc + tlmm + rpmh + qmpphy + g_serial";

	chosen {
		/*
		 * Byte-for-byte the round R command line with the tag changed.
		 * If this boot behaves differently from round R, the enabled
		 * QMP phy has to be the only reason it can.
		 */
		bootargs = "console=tty0 ignore_loglevel nokaslr maxcpus=1 clk_ignore_unused pd_ignore_unused regulator_ignore_unused panic=5 printk.devkmsg=on rdinit=/dada-init dada_probe=builtin-dtb-gpu root=/dev/sda36 rw rootwait loglevel=4 systemd.show_status=yes ath12k.mac_addr=CE:76:4A:AB:26:35 root=/dev/sda36 rw rootwait loglevel=4 systemd.show_status=yes";
	};
};

&usb_dp_qmpphy {
	/* The single variable. See the header comment. */
	status = "okay";
};

/ {
	model = "Xiaomi 15 (dada) mainline bring-up probe, pdc + tlmm + rpmh + qmpphy + g_serial + ttyGS0 console";

	chosen {
		/*
		 * The S command line plus console=ttyGS0,115200. ttynull
		 * stays first (early console); ttyGS0 last (preferred).
		 * Everything else is byte-for-byte round S.
		 */
		bootargs = "console=tty0 ignore_loglevel nokaslr maxcpus=1 clk_ignore_unused pd_ignore_unused regulator_ignore_unused panic=5 printk.devkmsg=on rdinit=/dada-init dada_probe=builtin-dtb-gpu root=/dev/sda36 rw rootwait loglevel=4 systemd.show_status=yes ath12k.mac_addr=CE:76:4A:AB:26:35 root=/dev/sda36 rw rootwait loglevel=4 systemd.show_status=yes";
	};
};

/ {
	model = "Xiaomi 15 (dada) mainline bring-up probe, pdc + tlmm + rpmh + qmpphy + g_serial + interactive shell";

	chosen {
		/*
		 * Byte-for-byte the round T command line with the tag changed.
		 * The shell lives in the initramfs; the kernel and this DT
		 * are otherwise round T's.
		 */
		bootargs = "console=tty0 ignore_loglevel nokaslr maxcpus=1 clk_ignore_unused pd_ignore_unused regulator_ignore_unused panic=5 printk.devkmsg=on rdinit=/dada-init dada_probe=builtin-dtb-gpu root=/dev/sda36 rw rootwait loglevel=4 systemd.show_status=yes ath12k.mac_addr=CE:76:4A:AB:26:35 root=/dev/sda36 rw rootwait loglevel=4 systemd.show_status=yes";
	};
};

/ {
	model = "Xiaomi 15 (dada) mainline bring-up probe, pdc + tlmm + rpmh + qmpphy + g_serial + interactive shell + spmi-pmic mfd";

	chosen {
		/*
		 * Byte-for-byte the round T command line with the tag changed.
		 * The shell lives in the initramfs; the kernel and this DT
		 * are otherwise round T's.
		 */
		bootargs = "console=tty0 ignore_loglevel nokaslr maxcpus=1 clk_ignore_unused pd_ignore_unused regulator_ignore_unused panic=5 printk.devkmsg=on rdinit=/dada-init dada_probe=builtin-dtb-gpu root=/dev/sda36 rw rootwait loglevel=4 systemd.show_status=yes ath12k.mac_addr=CE:76:4A:AB:26:35 root=/dev/sda36 rw rootwait loglevel=4 systemd.show_status=yes";
	};
};

/ {
	model = "Xiaomi 15 (dada) mainline bring-up probe, pdc + tlmm + rpmh + qmpphy + g_serial + shell + spmi-pmic + pmic children";

	chosen {
		bootargs = "console=tty0 ignore_loglevel nokaslr maxcpus=1 clk_ignore_unused pd_ignore_unused regulator_ignore_unused panic=5 printk.devkmsg=on rdinit=/dada-init dada_probe=builtin-dtb-gpu root=/dev/sda36 rw rootwait loglevel=4 systemd.show_status=yes ath12k.mac_addr=CE:76:4A:AB:26:35 root=/dev/sda36 rw rootwait loglevel=4 systemd.show_status=yes";
	};
};

/ {
	model = "Xiaomi 15 (dada) mainline bring-up probe, pdc + tlmm + rpmh + qmpphy + g_serial + shell + pmic children + observation";

	chosen {
		bootargs = "console=tty0 ignore_loglevel nokaslr maxcpus=1 clk_ignore_unused pd_ignore_unused regulator_ignore_unused panic=5 printk.devkmsg=on rdinit=/dada-init dada_probe=builtin-dtb-gpu root=/dev/sda36 rw rootwait loglevel=4 systemd.show_status=yes ath12k.mac_addr=CE:76:4A:AB:26:35 root=/dev/sda36 rw rootwait loglevel=4 systemd.show_status=yes";
	};
};

/ {
	model = "Xiaomi 15 (dada) mainline bring-up probe, pdc + tlmm + rpmh + qmpphy + g_serial + shell + pmic children + iommu";

	chosen {
		bootargs = "console=tty0 ignore_loglevel nokaslr maxcpus=1 clk_ignore_unused pd_ignore_unused regulator_ignore_unused panic=5 printk.devkmsg=on rdinit=/dada-init dada_probe=builtin-dtb-gpu root=/dev/sda36 rw rootwait loglevel=4 systemd.show_status=yes ath12k.mac_addr=CE:76:4A:AB:26:35 root=/dev/sda36 rw rootwait loglevel=4 systemd.show_status=yes";
	};
};

&tlmm {
	disp0_reset_n_active: disp0-reset-n-active-state {
		pins = "gpio98";
		function = "gpio";
		drive-strength = <8>;
		bias-disable;
	};

	disp0_reset_n_suspend: disp0-reset-n-suspend-state {
		pins = "gpio98";
		function = "gpio";
		drive-strength = <2>;
		bias-pull-down;
	};

	mdp_vsync: mdp-vsync-state {
		pins = "gpio86";
		function = "mdp_vsync";
		drive-strength = <2>;
		bias-pull-down;
	};
};

&apps_rsc {
	regulators-0 {
		vreg_l11b_1p0: ldo11 {
			regulator-name = "vreg_l11b_1p0";
			regulator-min-microvolt = <1064000>;
			regulator-max-microvolt = <1292000>;
			regulator-initial-mode = <RPMH_REGULATOR_MODE_HPM>;
			regulator-allow-set-load;
			regulator-allowed-modes = <RPMH_REGULATOR_MODE_LPM
						   RPMH_REGULATOR_MODE_HPM>;
		};

		vreg_l12b_1p8: ldo12 {
			regulator-name = "vreg_l12b_1p8";
			regulator-min-microvolt = <1200000>;
			regulator-max-microvolt = <1800000>;
			regulator-initial-mode = <RPMH_REGULATOR_MODE_HPM>;
			regulator-allow-set-load;
			regulator-allowed-modes = <RPMH_REGULATOR_MODE_LPM
						   RPMH_REGULATOR_MODE_HPM>;
		};

		vreg_l13b_3p0: ldo13 {
			regulator-name = "vreg_l13b_3p0";
			regulator-min-microvolt = <3000000>;
			regulator-max-microvolt = <3000000>;
			regulator-initial-mode = <RPMH_REGULATOR_MODE_HPM>;
			regulator-allow-set-load;
			regulator-allowed-modes = <RPMH_REGULATOR_MODE_LPM
						   RPMH_REGULATOR_MODE_HPM>;
		};

		/* Touch Round CN: stock pm_humu_l16 = ldob16 (avdd, 3.0 V fixed;
		 * runtime.dts 29796-29805 min=max=init=0x2dc6c0 = 3000000 uV) */
		vreg_l16b_3p0: ldo16 {
			regulator-name = "vreg_l16b_3p0";
			regulator-min-microvolt = <3000000>;
			regulator-max-microvolt = <3000000>;
			regulator-initial-mode = <RPMH_REGULATOR_MODE_HPM>;
			regulator-allow-set-load;
			regulator-allowed-modes = <RPMH_REGULATOR_MODE_LPM
						   RPMH_REGULATOR_MODE_HPM>;
		};
	};

	regulators-1 {
		vreg_l3i_0p88: ldo3 {
			regulator-name = "vreg_l3i_0p88";
			regulator-min-microvolt = <880000>;
			regulator-max-microvolt = <880000>;
			regulator-initial-mode = <RPMH_REGULATOR_MODE_HPM>;
		};
	};
};

&mdss {
	status = "okay";
};

&mdss_dsi0 {
	vdda-supply = <&vreg_l3g_1p2>;

	status = "okay";

	panel@0 {
		compatible = "novatek,nt37801";
		reg = <0>;

		reset-gpios = <&tlmm 98 GPIO_ACTIVE_LOW>;

		vddio-supply = <&vreg_l12b_1p8>;
		vci-supply = <&vreg_l13b_3p0>;
		vdd-supply = <&vreg_l11b_1p0>;

		pinctrl-0 = <&disp0_reset_n_active>, <&mdp_vsync>;
		pinctrl-1 = <&disp0_reset_n_suspend>, <&mdp_vsync>;
		pinctrl-names = "default", "sleep";

		port {
			panel0_in: endpoint {
				remote-endpoint = <&mdss_dsi0_out>;
			};
		};
	};
};

&mdss_dsi0_out {
	remote-endpoint = <&panel0_in>;
	data-lanes = <0 1 2 3>;
};

&mdss_dsi0_phy {
	vdds-supply = <&vreg_l3i_0p88>;

	status = "okay";
};

/ {
	model = "Xiaomi 15 (dada) mainline bring-up probe, pdc + tlmm + rpmh + qmpphy + g_serial + shell + pmic children + iommu + drm-msm nt37801";

	chosen {
		bootargs = "console=tty0 ignore_loglevel nokaslr maxcpus=1 clk_ignore_unused pd_ignore_unused regulator_ignore_unused panic=5 printk.devkmsg=on rdinit=/dada-init dada_probe=builtin-dtb-gpu root=/dev/sda36 rw rootwait loglevel=4 systemd.show_status=yes ath12k.mac_addr=CE:76:4A:AB:26:35 root=/dev/sda36 rw rootwait loglevel=4 systemd.show_status=yes";
	};
};

/ {
	model = "Xiaomi 15 (dada) mainline bring-up probe, display + smem";

	chosen {
		bootargs = "console=tty0 ignore_loglevel nokaslr maxcpus=1 clk_ignore_unused pd_ignore_unused regulator_ignore_unused panic=5 printk.devkmsg=on rdinit=/dada-init dada_probe=builtin-dtb-gpu root=/dev/sda36 rw rootwait loglevel=4 systemd.show_status=yes ath12k.mac_addr=CE:76:4A:AB:26:35 root=/dev/sda36 rw rootwait loglevel=4 systemd.show_status=yes";
	};
};

/ {
	model = "Xiaomi 15 (dada) mainline bring-up probe, display + smem + dpu-fini-guard";

	chosen {
		bootargs = "console=tty0 ignore_loglevel nokaslr maxcpus=1 clk_ignore_unused pd_ignore_unused regulator_ignore_unused panic=5 printk.devkmsg=on rdinit=/dada-init dada_probe=builtin-dtb-gpu root=/dev/sda36 rw rootwait loglevel=4 systemd.show_status=yes ath12k.mac_addr=CE:76:4A:AB:26:35 root=/dev/sda36 rw rootwait loglevel=4 systemd.show_status=yes";
	};
};

/ {
	model = "Xiaomi 15 (dada) mainline bring-up probe, display + smem + fini-guard + log-tail";

	chosen {
		bootargs = "console=tty0 ignore_loglevel nokaslr maxcpus=1 clk_ignore_unused pd_ignore_unused regulator_ignore_unused panic=5 printk.devkmsg=on rdinit=/dada-init dada_probe=builtin-dtb-gpu root=/dev/sda36 rw rootwait loglevel=4 systemd.show_status=yes ath12k.mac_addr=CE:76:4A:AB:26:35 root=/dev/sda36 rw rootwait loglevel=4 systemd.show_status=yes";
	};
};

/ {
	model = "Xiaomi 15 (dada) mainline bring-up probe, display + smem + fini-guard + smmu";

	chosen {
		bootargs = "console=tty0 ignore_loglevel nokaslr maxcpus=1 clk_ignore_unused pd_ignore_unused regulator_ignore_unused panic=5 printk.devkmsg=on rdinit=/dada-init dada_probe=builtin-dtb-gpu root=/dev/sda36 rw rootwait loglevel=4 systemd.show_status=yes ath12k.mac_addr=CE:76:4A:AB:26:35 root=/dev/sda36 rw rootwait loglevel=4 systemd.show_status=yes";
	};
};

/ {
	model = "Xiaomi 15 (dada) mainline bring-up probe, display + smem + fini-guard + smmu + o3 panel";

	chosen {
		bootargs = "console=tty0 ignore_loglevel nokaslr maxcpus=1 clk_ignore_unused pd_ignore_unused regulator_ignore_unused panic=5 printk.devkmsg=on rdinit=/dada-init dada_probe=builtin-dtb-gpu root=/dev/sda36 rw rootwait loglevel=4 systemd.show_status=yes ath12k.mac_addr=CE:76:4A:AB:26:35 root=/dev/sda36 rw rootwait loglevel=4 systemd.show_status=yes";
	};

	display_panel_vddd: regulator-display-panel-vddd {
		compatible = "regulator-fixed";
		regulator-name = "display_panel_vddd";
		regulator-min-microvolt = <1200000>;
		regulator-max-microvolt = <1200000>;
		gpio = <&tlmm 120 GPIO_ACTIVE_HIGH>;
		enable-active-high;
		regulator-boot-on;
		pinctrl-names = "default";
		pinctrl-0 = <&display_panel_vddd_gpio>;
	};
};

&tlmm {
	display_panel_vddd_gpio: display-panel-vddd-gpio-state {
		pins = "gpio120";
		function = "gpio";
		drive-strength = <2>;
		bias-disable;
	};
};

&apps_rsc {
	regulators-3 {
		/* The g-side LDO the vendor feeds the panel's vddio from
		 * (regulator-pm-v8g-l2 in the runtime tree); values from
		 * upstream sm8750-mtp.dts, whose vdd-l2 parent (s3g) the
		 * regulators-3 block already declares. */
		vreg_l2g_1p8: ldo2 {
			regulator-name = "vreg_l2g_1p8";
			regulator-min-microvolt = <1200000>;
			regulator-max-microvolt = <1860000>;
			regulator-initial-mode = <RPMH_REGULATOR_MODE_HPM>;
			regulator-allow-set-load;
			regulator-allowed-modes = <RPMH_REGULATOR_MODE_LPM
						   RPMH_REGULATOR_MODE_HPM>;
		};
	};
};

&mdss_dsi0 {
	panel@0 {
		compatible = "xiaomi,dada-o3";

		vddio-supply = <&vreg_l2g_1p8>;
		vci-supply = <&vreg_l13b_3p0>;
		vddd-supply = <&display_panel_vddd>;
		/delete-property/ vdd-supply;
	};
};

/ {
	model = "Xiaomi 15 (dada) mainline bring-up probe, display + smem + fini-guard + smmu + o3 panel + readback";

	chosen {
		bootargs = "console=tty0 ignore_loglevel nokaslr maxcpus=1 clk_ignore_unused pd_ignore_unused regulator_ignore_unused panic=5 printk.devkmsg=on rdinit=/dada-init dada_probe=builtin-dtb-gpu root=/dev/sda36 rw rootwait loglevel=4 systemd.show_status=yes ath12k.mac_addr=CE:76:4A:AB:26:35 root=/dev/sda36 rw rootwait loglevel=4 systemd.show_status=yes";
	};
};

/ {
	model = "Xiaomi 15 (dada) mainline bring-up probe, display + smem + fini-guard + smmu + o3 panel + 1 read";

	chosen {
		bootargs = "console=tty0 ignore_loglevel nokaslr maxcpus=1 clk_ignore_unused pd_ignore_unused regulator_ignore_unused panic=5 printk.devkmsg=on rdinit=/dada-init dada_probe=builtin-dtb-gpu root=/dev/sda36 rw rootwait loglevel=4 systemd.show_status=yes ath12k.mac_addr=CE:76:4A:AB:26:35 root=/dev/sda36 rw rootwait loglevel=4 systemd.show_status=yes";
	};
};

/ {
	model = "Xiaomi 15 (dada) mainline bring-up probe, display + smem + fini-guard + smmu + o3 panel + read sweep";

	chosen {
		bootargs = "console=tty0 ignore_loglevel nokaslr maxcpus=1 clk_ignore_unused pd_ignore_unused regulator_ignore_unused panic=5 printk.devkmsg=on rdinit=/dada-init dada_probe=builtin-dtb-gpu root=/dev/sda36 rw rootwait loglevel=4 systemd.show_status=yes ath12k.mac_addr=CE:76:4A:AB:26:35 root=/dev/sda36 rw rootwait loglevel=4 systemd.show_status=yes";
	};
};

/ {
	model = "Xiaomi 15 (dada) mainline bring-up probe, display + smem + fini-guard + smmu + o3 panel + bl readback";

	chosen {
		bootargs = "console=tty0 ignore_loglevel nokaslr maxcpus=1 clk_ignore_unused pd_ignore_unused regulator_ignore_unused panic=5 printk.devkmsg=on rdinit=/dada-init dada_probe=builtin-dtb-gpu root=/dev/sda36 rw rootwait loglevel=4 systemd.show_status=yes ath12k.mac_addr=CE:76:4A:AB:26:35 root=/dev/sda36 rw rootwait loglevel=4 systemd.show_status=yes";
	};
};

/ {
	model = "Xiaomi 15 (dada) mainline bring-up probe, display + smem + fini-guard + smmu + o3 panel + bl readback + dsc link cfg";

	chosen {
		bootargs = "console=tty0 ignore_loglevel nokaslr maxcpus=1 clk_ignore_unused pd_ignore_unused regulator_ignore_unused panic=5 printk.devkmsg=on rdinit=/dada-init dada_probe=builtin-dtb-gpu root=/dev/sda36 rw rootwait loglevel=4 systemd.show_status=yes ath12k.mac_addr=CE:76:4A:AB:26:35 root=/dev/sda36 rw rootwait loglevel=4 systemd.show_status=yes";
	};
};

/ {
	model = "Xiaomi 15 (dada) mainline bring-up probe, display + smem + fini-guard + smmu + o3 panel + bl readback + dsc link cfg + splash handover";

	chosen {
		bootargs = "console=tty0 ignore_loglevel nokaslr maxcpus=1 clk_ignore_unused pd_ignore_unused regulator_ignore_unused panic=5 printk.devkmsg=on rdinit=/dada-init dada_probe=builtin-dtb-gpu root=/dev/sda36 rw rootwait loglevel=4 systemd.show_status=yes ath12k.mac_addr=CE:76:4A:AB:26:35 root=/dev/sda36 rw rootwait loglevel=4 systemd.show_status=yes";
	};
};

/* The round-AK variable: keep the ABL splash translations alive across
 * the kernel's SMMU takeover so the handoff cannot fault-terminate a
 * stalled MDSS fetch and wedge the bus. Identity mapping: the iova
 * equals the physical address of the region. The plain cont-splash node
 * from the base probe tree is deleted and re-added with the
 * iommu-addresses property -- same address and size, one node, no
 * overlap.
 *
 * NODE NAME: must be exactly "splash_region", with NO unit address.
 * Qualcomm's ABL looks the region up by the literal path
 * /reserved-memory/splash_region; if it cannot find it, it tears the
 * display down instead of handing a live framebuffer to the kernel.
 * This is the form the device's own stock DT uses -- see
 * device-tree/runtime.dts:703 (node "splash_region", no unit address,
 * label = "cont_splash_region", same reg) and the stock dtbo overlay.
 * Upstream carries the same warning on two Samsung boards, e.g.
 * arch/arm64/boot/dts/qcom/sm8450-samsung-r0q.dts:43 ("The bootloader
 * will only keep display hardware enabled if this memory region is
 * named exactly 'splash_region'"). A reserved-memory child with no
 * unit address is a legal form -- dtc builds this clean, no
 * unit_address_vs_reg warning. */
&{/reserved-memory} {
	/delete-node/ cont-splash@fc800000;

	cont_splash_ak: splash_region {
		reg = <0x0 0xfc800000 0x0 0x2b00000>;
		iommu-addresses = <&mdss 0x0 0xfc800000 0x0 0x2b00000>;
		label = "cont_splash_region";
		no-map;
	};
};

&mdss {
	memory-region = <&cont_splash_ak>;
};

/ {
	model = "Xiaomi 15 (dada) mainline bring-up probe, display + smem + fini-guard + smmu + o3 panel + bl readback + dsc link cfg + splash handover + vendor dsc table";

	chosen {
		bootargs = "console=tty0 ignore_loglevel nokaslr maxcpus=1 clk_ignore_unused pd_ignore_unused regulator_ignore_unused panic=5 printk.devkmsg=on rdinit=/dada-init dada_probe=builtin-dtb-gpu root=/dev/sda36 rw rootwait loglevel=4 systemd.show_status=yes ath12k.mac_addr=CE:76:4A:AB:26:35 root=/dev/sda36 rw rootwait loglevel=4 systemd.show_status=yes";
	};
};

/ {
	model = "Xiaomi 15 (dada) mainline bring-up probe, display + smem + fini-guard + smmu + o3 panel + bl readback + dsc link cfg + splash handover + vendor dsc table + vendor dsc rc config + raw blob pps bit4";

	chosen {
		bootargs = "console=tty0 ignore_loglevel nokaslr maxcpus=1 clk_ignore_unused pd_ignore_unused regulator_ignore_unused panic=5 printk.devkmsg=on rdinit=/dada-init dada_probe=builtin-dtb-gpu root=/dev/sda36 rw rootwait loglevel=4 systemd.show_status=yes ath12k.mac_addr=CE:76:4A:AB:26:35 root=/dev/sda36 rw rootwait loglevel=4 systemd.show_status=yes";
	};
};

/ {
	model = "Xiaomi 15 (dada) mainline bring-up probe, display + smem + fini-guard + smmu + o3 panel + bl readback + dsc link cfg + splash handover + vendor dsc table + vendor dsc rc config + raw blob pps bit4 + n422 clear";

	chosen {
		bootargs = "console=tty0 ignore_loglevel nokaslr maxcpus=1 clk_ignore_unused pd_ignore_unused regulator_ignore_unused panic=5 printk.devkmsg=on rdinit=/dada-init dada_probe=builtin-dtb-gpu root=/dev/sda36 rw rootwait loglevel=4 systemd.show_status=yes ath12k.mac_addr=CE:76:4A:AB:26:35 root=/dev/sda36 rw rootwait loglevel=4 systemd.show_status=yes";
	};
};

/ {
	model = "Xiaomi 15 (dada) mainline bring-up probe, display + smem + fini-guard + smmu + o3 panel + bl readback + dsc link cfg + splash handover + vendor dsc table + vendor dsc rc config + raw blob pps bit4 + n422 clear + vendor initial lines";

	chosen {
		bootargs = "console=tty0 ignore_loglevel nokaslr maxcpus=1 clk_ignore_unused pd_ignore_unused regulator_ignore_unused panic=5 printk.devkmsg=on rdinit=/dada-init dada_probe=builtin-dtb-gpu root=/dev/sda36 rw rootwait loglevel=4 systemd.show_status=yes ath12k.mac_addr=CE:76:4A:AB:26:35 root=/dev/sda36 rw rootwait loglevel=4 systemd.show_status=yes";
	};
};

/ {
	model = "Xiaomi 15 (dada) mainline bring-up probe, display + smem + fini-guard + smmu + o3 panel + bl readback + dsc link cfg + splash handover + vendor dsc table + vendor dsc rc config + raw blob pps bit4 + n422 clear + vendor initial lines + stay + bpp revert";

	chosen {
		bootargs = "console=tty0 ignore_loglevel nokaslr maxcpus=1 clk_ignore_unused pd_ignore_unused regulator_ignore_unused panic=5 printk.devkmsg=on rdinit=/dada-init dada_probe=builtin-dtb-gpu root=/dev/sda36 rw rootwait loglevel=4 systemd.show_status=yes ath12k.mac_addr=CE:76:4A:AB:26:35 root=/dev/sda36 rw rootwait loglevel=4 systemd.show_status=yes dada_stay";
	};
};

/ {
	model = "Xiaomi 15 (dada) mainline bring-up probe, display + smem + fini-guard + smmu + o3 panel + bl readback + dsc link cfg + splash handover + vendor dsc table + vendor dsc rc config + raw blob pps bit4 + n422 clear + vendor initial lines + stay + content + dsc bpp 128/128 + vt quiesce + paced log + no test pattern + u_serial console fix + splash rename";

	chosen {
		bootargs = "console=tty0 ignore_loglevel nokaslr maxcpus=1 clk_ignore_unused pd_ignore_unused regulator_ignore_unused panic=5 printk.devkmsg=on rdinit=/dada-init dada_probe=builtin-dtb-gpu root=/dev/sda36 rw rootwait loglevel=4 systemd.show_status=yes ath12k.mac_addr=CE:76:4A:AB:26:35 root=/dev/sda36 rw rootwait loglevel=4 systemd.show_status=yes dada_stay panel_xiaomi_dada_o3.pps_bpp=128 panel_xiaomi_dada_o3.enc_bpp=128 panel_xiaomi_dada_o3.dsc_native_422=1 panel_xiaomi_dada_o3.dsc_cvt_rgb=0";
	};
};

/ {
	model = "Xiaomi 15 (dada) mainline bring-up probe, display + smem + fini-guard + smmu + o3 panel + bl readback + dsc link cfg + splash handover + vendor dsc table + vendor dsc rc config + raw blob pps bit4 + n422 clear + vendor initial lines + stay + content + dsc bpp 128/128 + vt quiesce + paced log + no test pattern + u_serial console fix + splash rename + sm8750 mdss identity";

	chosen {
		bootargs = "console=tty0 ignore_loglevel nokaslr maxcpus=1 clk_ignore_unused pd_ignore_unused regulator_ignore_unused panic=5 printk.devkmsg=on rdinit=/dada-init dada_probe=builtin-dtb-gpu root=/dev/sda36 rw rootwait loglevel=4 systemd.show_status=yes ath12k.mac_addr=CE:76:4A:AB:26:35 root=/dev/sda36 rw rootwait loglevel=4 systemd.show_status=yes dada_stay panel_xiaomi_dada_o3.pps_bpp=128 panel_xiaomi_dada_o3.enc_bpp=128 panel_xiaomi_dada_o3.dsc_native_422=1 panel_xiaomi_dada_o3.dsc_cvt_rgb=0";
	};
};

/ {
	model = "Xiaomi 15 (dada) mainline bring-up probe, display + smem + fini-guard + smmu + o3 panel + bl readback + dsc link cfg + splash handover + vendor dsc table + vendor dsc rc config + raw blob pps bit4 + n422 clear + vendor initial lines + stay + content + dsc bpp 128/128 + vt quiesce + paced log + no test pattern + u_serial console fix + splash rename + sm8750 mdss identity + ufs read + ro mount";

	chosen {
		bootargs = "console=tty0 ignore_loglevel nokaslr maxcpus=1 clk_ignore_unused pd_ignore_unused regulator_ignore_unused panic=5 printk.devkmsg=on rdinit=/dada-init dada_probe=builtin-dtb-gpu root=/dev/sda36 rw rootwait loglevel=4 systemd.show_status=yes ath12k.mac_addr=CE:76:4A:AB:26:35 root=/dev/sda36 rw rootwait loglevel=4 systemd.show_status=yes dada_stay panel_xiaomi_dada_o3.pps_bpp=128 panel_xiaomi_dada_o3.enc_bpp=128 panel_xiaomi_dada_o3.dsc_native_422=1 panel_xiaomi_dada_o3.dsc_cvt_rgb=0";
	};
};

/ {
	model = "Xiaomi 15 (dada) mainline bring-up probe, display + smem + fini-guard + smmu + o3 panel + bl readback + dsc link cfg + splash handover + vendor dsc table + vendor dsc rc config + raw blob pps bit4 + n422 clear + vendor initial lines + stay + content + dsc bpp 128/128 + vt quiesce + paced log + no test pattern + u_serial console fix + splash rename + sm8750 mdss identity + ufs read + ro mount + sb magic";

	chosen {
		bootargs = "console=tty0 ignore_loglevel nokaslr maxcpus=1 clk_ignore_unused pd_ignore_unused regulator_ignore_unused panic=5 printk.devkmsg=on rdinit=/dada-init dada_probe=builtin-dtb-gpu root=/dev/sda36 rw rootwait loglevel=4 systemd.show_status=yes ath12k.mac_addr=CE:76:4A:AB:26:35 root=/dev/sda36 rw rootwait loglevel=4 systemd.show_status=yes dada_stay panel_xiaomi_dada_o3.pps_bpp=128 panel_xiaomi_dada_o3.enc_bpp=128 panel_xiaomi_dada_o3.dsc_native_422=1 panel_xiaomi_dada_o3.dsc_cvt_rgb=0";
	};
};

/ {
	model = "Xiaomi 15 (dada) mainline bring-up probe, display + smem + fini-guard + smmu + o3 panel + bl readback + dsc link cfg + splash handover + vendor dsc table + vendor dsc rc config + raw blob pps bit4 + n422 clear + vendor initial lines + stay + content + dsc bpp 128/128 + vt quiesce + paced log + no test pattern + u_serial console fix + splash rename + sm8750 mdss identity + ufs read + ro mount + sb magic + usb net + backlight adjust + ms lun removable";

	chosen {
		bootargs = "console=tty0 ignore_loglevel nokaslr maxcpus=1 clk_ignore_unused pd_ignore_unused regulator_ignore_unused panic=5 printk.devkmsg=on rdinit=/dada-init dada_probe=builtin-dtb-gpu root=/dev/sda36 rw rootwait loglevel=4 systemd.show_status=yes ath12k.mac_addr=CE:76:4A:AB:26:35 root=/dev/sda36 rw rootwait loglevel=4 systemd.show_status=yes dada_stay g_multi.removable=1 panel_xiaomi_dada_o3.pps_bpp=128 panel_xiaomi_dada_o3.enc_bpp=128 panel_xiaomi_dada_o3.dsc_native_422=1 panel_xiaomi_dada_o3.dsc_cvt_rgb=0";
	};
};

/ {
	model = "Xiaomi 15 (dada) mainline bring-up probe, display + smem + fini-guard + smmu + o3 panel + bl readback + dsc link cfg + splash handover + vendor dsc table + vendor dsc rc config + raw blob pps bit4 + n422 clear + vendor initial lines + stay + content + dsc bpp 128/128 + vt quiesce + paced log + no test pattern + u_serial console fix + splash rename + sm8750 mdss identity + ufs read + ro mount + sb magic + usb net + backlight adjust + ms lun removable + loopback rootfs";

	chosen {
		bootargs = "console=tty0 ignore_loglevel nokaslr maxcpus=1 clk_ignore_unused pd_ignore_unused regulator_ignore_unused panic=5 printk.devkmsg=on rdinit=/dada-init dada_probe=builtin-dtb-gpu root=/dev/sda36 rw rootwait loglevel=4 systemd.show_status=yes ath12k.mac_addr=CE:76:4A:AB:26:35 root=/dev/sda36 rw rootwait loglevel=4 systemd.show_status=yes dada_stay panel_xiaomi_dada_o3.pps_bpp=128 panel_xiaomi_dada_o3.enc_bpp=128 panel_xiaomi_dada_o3.dsc_native_422=1 panel_xiaomi_dada_o3.dsc_cvt_rgb=0";
	};
};

/ {
	model = "Xiaomi 15 (dada) mainline bring-up probe, display + smem + fini-guard + smmu + o3 panel + bl readback + dsc link cfg + splash handover + vendor dsc table + vendor dsc rc config + raw blob pps bit4 + n422 clear + vendor initial lines + stay + content + dsc bpp 128/128 + vt quiesce + paced log + no test pattern + u_serial console fix + splash rename + sm8750 mdss identity + ufs read + ro mount + sb magic + usb net + backlight adjust + ms lun removable + loopback rootfs + splash direct-map";

	chosen {
		bootargs = "console=tty0 ignore_loglevel nokaslr maxcpus=1 clk_ignore_unused pd_ignore_unused regulator_ignore_unused panic=5 printk.devkmsg=on rdinit=/dada-init dada_probe=builtin-dtb-gpu root=/dev/sda36 rw rootwait loglevel=4 systemd.show_status=yes ath12k.mac_addr=CE:76:4A:AB:26:35 root=/dev/sda36 rw rootwait loglevel=4 systemd.show_status=yes dada_stay panel_xiaomi_dada_o3.pps_bpp=128 panel_xiaomi_dada_o3.enc_bpp=128 panel_xiaomi_dada_o3.dsc_native_422=1 panel_xiaomi_dada_o3.dsc_cvt_rgb=0";
	};
};

/ {
	model = "Xiaomi 15 (dada) mainline bring-up probe, display + smem + fini-guard + smmu + o3 panel + bl readback + dsc link cfg + splash handover + vendor dsc table + vendor dsc rc config + raw blob pps bit4 + n422 clear + vendor initial lines + stay + content + dsc bpp 128/128 + vt quiesce + paced log + no test pattern + u_serial console fix + splash rename + sm8750 mdss identity + ufs read + ro mount + sb magic + usb net + backlight adjust + ms lun removable + loopback rootfs + splash direct-map + pre-arm cmd engine reset";

	chosen {
		bootargs = "console=tty0 ignore_loglevel nokaslr maxcpus=1 clk_ignore_unused pd_ignore_unused regulator_ignore_unused panic=5 printk.devkmsg=on rdinit=/dada-init dada_probe=builtin-dtb-gpu root=/dev/sda36 rw rootwait loglevel=4 systemd.show_status=yes ath12k.mac_addr=CE:76:4A:AB:26:35 root=/dev/sda36 rw rootwait loglevel=4 systemd.show_status=yes dada_stay panel_xiaomi_dada_o3.pps_bpp=128 panel_xiaomi_dada_o3.enc_bpp=128 panel_xiaomi_dada_o3.dsc_native_422=1 panel_xiaomi_dada_o3.dsc_cvt_rgb=0";
	};
};

/ {
	model = "Xiaomi 15 (dada) mainline bring-up probe, display + smem + fini-guard + smmu + o3 panel + bl readback + dsc link cfg + splash handover + vendor dsc table + vendor dsc rc config + raw blob pps bit4 + n422 clear + vendor initial lines + stay + content + dsc bpp 128/128 + vt quiesce + paced log + no test pattern + u_serial console fix + splash rename + sm8750 mdss identity + ufs read + ro mount + sb magic + usb net + backlight adjust + ms lun removable + loopback rootfs + splash direct-map + pre-arm cmd engine reset + no embedded rootfs";

	chosen {
		bootargs = "console=tty0 ignore_loglevel nokaslr maxcpus=1 clk_ignore_unused pd_ignore_unused regulator_ignore_unused panic=5 printk.devkmsg=on rdinit=/dada-init dada_probe=builtin-dtb-gpu root=/dev/sda36 rw rootwait loglevel=4 systemd.show_status=yes ath12k.mac_addr=CE:76:4A:AB:26:35 root=/dev/sda36 rw rootwait loglevel=4 systemd.show_status=yes dada_stay panel_xiaomi_dada_o3.pps_bpp=128 panel_xiaomi_dada_o3.enc_bpp=128 panel_xiaomi_dada_o3.dsc_native_422=1 panel_xiaomi_dada_o3.dsc_cvt_rgb=0";
	};
};

/ {
	model = "Xiaomi 15 (dada) mainline bring-up probe, display + smem + fini-guard + smmu + o3 panel + bl readback + dsc link cfg + splash handover + vendor dsc table + vendor dsc rc config + raw blob pps bit4 + n422 clear + vendor initial lines + stay + content + dsc bpp 128/128 + vt quiesce + paced log + no test pattern + u_serial console fix + splash rename + sm8750 mdss identity + ufs read + ro mount + sb magic + usb net + backlight adjust + ms lun removable + loopback rootfs + splash direct-map + no embedded rootfs + dsi_host restored to BL";

	chosen {
		bootargs = "console=tty0 ignore_loglevel nokaslr maxcpus=1 clk_ignore_unused pd_ignore_unused regulator_ignore_unused panic=5 printk.devkmsg=on rdinit=/dada-init dada_probe=builtin-dtb-gpu root=/dev/sda36 rw rootwait loglevel=4 systemd.show_status=yes ath12k.mac_addr=CE:76:4A:AB:26:35 root=/dev/sda36 rw rootwait loglevel=4 systemd.show_status=yes dada_stay panel_xiaomi_dada_o3.pps_bpp=128 panel_xiaomi_dada_o3.enc_bpp=128 panel_xiaomi_dada_o3.dsc_native_422=1 panel_xiaomi_dada_o3.dsc_cvt_rgb=0";
	};
};

/ {
	model = "Xiaomi 15 (dada) mainline bring-up probe, display + smem + fini-guard + smmu + o3 panel + bl readback + dsc link cfg + splash handover + vendor dsc table + vendor dsc rc config + raw blob pps bit4 + n422 clear + vendor initial lines + stay + content + dsc bpp 128/128 + vt quiesce + paced log + no test pattern + u_serial console fix + splash rename + sm8750 mdss identity + ufs read + ro mount + sb magic + usb net + backlight adjust + ms lun removable + loopback rootfs + splash direct-map + no embedded rootfs + dsi_host restored to BL + pivot to rescue rootfs";

	chosen {
		bootargs = "console=tty0 ignore_loglevel nokaslr maxcpus=1 clk_ignore_unused pd_ignore_unused regulator_ignore_unused panic=5 printk.devkmsg=on rdinit=/dada-init dada_probe=builtin-dtb-gpu root=/dev/sda36 rw rootwait loglevel=4 systemd.show_status=yes ath12k.mac_addr=CE:76:4A:AB:26:35 root=/dev/sda36 rw rootwait loglevel=4 systemd.show_status=yes dada_stay dada_pivot panel_xiaomi_dada_o3.pps_bpp=128 panel_xiaomi_dada_o3.enc_bpp=128 panel_xiaomi_dada_o3.dsc_native_422=1 panel_xiaomi_dada_o3.dsc_cvt_rgb=0";
	};
};

/ {
	model = "Xiaomi 15 (dada) mainline bring-up probe, display + smem + fini-guard + smmu + o3 panel + bl readback + dsc link cfg + splash handover + vendor dsc table + vendor dsc rc config + raw blob pps bit4 + n422 clear + vendor initial lines + stay + content + dsc bpp 128/128 + vt quiesce + paced log + no test pattern + u_serial console fix + splash rename + sm8750 mdss identity + ufs read + ro mount + sb magic + usb net + backlight adjust + ms lun removable + loopback rootfs + splash direct-map + no embedded rootfs + dsi_host restored to BL + pivot to rescue rootfs + tsens";

	chosen {
		bootargs = "console=tty0 ignore_loglevel nokaslr maxcpus=1 clk_ignore_unused pd_ignore_unused regulator_ignore_unused panic=5 printk.devkmsg=on rdinit=/dada-init dada_probe=builtin-dtb-gpu root=/dev/sda36 rw rootwait loglevel=4 systemd.show_status=yes ath12k.mac_addr=CE:76:4A:AB:26:35 root=/dev/sda36 rw rootwait loglevel=4 systemd.show_status=yes dada_stay dada_pivot panel_xiaomi_dada_o3.pps_bpp=128 panel_xiaomi_dada_o3.enc_bpp=128 panel_xiaomi_dada_o3.dsc_native_422=1 panel_xiaomi_dada_o3.dsc_cvt_rgb=0";
	};
};

/ {
	model = "Xiaomi 15 (dada) mainline bring-up probe, display + smem + fini-guard + smmu + o3 panel + bl readback + dsc link cfg + splash handover + vendor dsc table + vendor dsc rc config + raw blob pps bit4 + n422 clear + vendor initial lines + stay + content + dsc bpp 128/128 + vt quiesce + paced log + no test pattern + u_serial console fix + splash rename + sm8750 mdss identity + ufs read + ro mount + sb magic + usb net + backlight adjust + ms lun removable + loopback rootfs + splash direct-map + no embedded rootfs + dsi_host restored to BL + pivot to rescue rootfs + tsens + splash-handover robust (iommu gap + clean dsi reset)";

	chosen {
		bootargs = "console=tty0 ignore_loglevel nokaslr maxcpus=1 clk_ignore_unused pd_ignore_unused regulator_ignore_unused panic=5 printk.devkmsg=on rdinit=/dada-init dada_probe=builtin-dtb-gpu root=/dev/sda36 rw rootwait loglevel=4 systemd.show_status=yes ath12k.mac_addr=CE:76:4A:AB:26:35 root=/dev/sda36 rw rootwait loglevel=4 systemd.show_status=yes dada_stay dada_pivot panel_xiaomi_dada_o3.pps_bpp=128 panel_xiaomi_dada_o3.enc_bpp=128 panel_xiaomi_dada_o3.dsc_native_422=1 panel_xiaomi_dada_o3.dsc_cvt_rgb=0";
	};
};

/ {
	model = "Xiaomi 15 (dada) mainline bring-up probe, display + smem + fini-guard + smmu + o3 panel + bl readback + dsc link cfg + splash handover + vendor dsc table + vendor dsc rc config + raw blob pps bit4 + n422 clear + vendor initial lines + stay + content + dsc bpp 128/128 + vt quiesce + paced log + no test pattern + u_serial console fix + splash rename + sm8750 mdss identity + ufs read + ro mount + sb magic + usb net + backlight adjust + ms lun removable + loopback rootfs + splash direct-map + no embedded rootfs + dsi_host restored to BL + pivot to rescue rootfs + tsens + splash-handover robust + SMP all 8 cores";

	chosen {
		/* Single variable vs CA: maxcpus=1 removed. */
		bootargs = "console=tty0 nokaslr clk_ignore_unused pd_ignore_unused regulator_ignore_unused panic=4 printk.devkmsg=on rdinit=/dada-init dada_probe=builtin-dtb-gpu root=/dev/sda36 rw rootwait loglevel=4 systemd.show_status=yes ath12k.mac_addr=CE:76:4A:AB:26:35 root=/dev/sda36 rw rootwait loglevel=4 systemd.show_status=yes dada_stay dada_pivot panel_xiaomi_dada_o3.pps_bpp=128 panel_xiaomi_dada_o3.enc_bpp=128 panel_xiaomi_dada_o3.dsc_native_422=1 panel_xiaomi_dada_o3.dsc_cvt_rgb=0";

	};
};

/*
 * Adreno 830 (0x44050001) — GPU / GMU / GPUCC / GXCLKCTL / Adreno SMMU / qfprom
 *
 * 加在板级而不是 sm8750.dtsi：构建脚本 STEP 5 只把本文件 sed 进内核树，
 * 保持内核树 dtsi 干净（改动全部收敛到单一证据文件）。
 *
 * 相对参考实现（tb322fc / GEEKiDoS Y700 Gen4）的三处必要修正：
 *   1. compatible 写 qcom,adreno-44050001（不是 44050000）。find_chipid() 走
 *      sscanf("qcom,adreno-%08x") 得 0x44050001，正好命中本树
 *      a6xx_catalog.c 的 ADRENO_CHIP_IDS(0x44050001)；参考树的 0x44050000
 *      只匹配它自己那份 catalog。stock DT 的 qcom,chipid 亦为 0x44050001。
 *   2. qfprom 用 qcom,sun-qfprom（stock 原串）。本树 drivers/nvmem/qfprom.c
 *      没有 qcom,sm8750-qfprom 匹配项，用它会读不出 speed_bin，
 *      supported_hw 退化为 BIT(0) → 只能命中最低档 OPP。
 *   3. interconnect 用 &gem_noc（本树 sm8750.dtsi 里的 qcom,sm8750-gem-noc，
 *      [MASTER_GFX3D] = &qnm_gpu 存在）。glymur.dtsi 的 hsc_noc 在 glymur.dtsi
 *      里，板级 include 链拿不到。
 *
 * OPP supported-hw 用本树 catalog 的 6 档 speedbins
 *   {0,0}{252,0}{242,1}{232,2}{221,3}{190,4} → BIT(0..4)
 * a6xx_set_supported_hw() 直接用 nvmem 熔丝值取 BIT(speedbin)，
 * dada 实际熔丝落在 BIT(1..4) = 0x2/0x4/0x8/0x10，故掩码为
 *   1100MHz  0x6  (242+232)
 *   1050/967 0xe  (+221)
 *   <=900MHz 0x1e (+190)
 * 参考实现的 0xc/0xe/0xf 基于它自己那套 4 档 speedbins，抄过来会错档。
 *
 * 不写 zap-shader 子节点：没 gen80000_zap.mbn，且空子节点会让
 * zap_shader_load_mdt() 返回 -ENODEV（a8xx_hw_init 容忍并回退
 * REG_A6XX_RBBM_SECVID_TRUST_CNTL=0）；非空但错误的子节点则直接中止 probe。
 * sm8750.dtsi 里已有的 gpu_micro_code_mem 因此保持 no-map 但无人引用。
 */
&soc {
	qfprom: efuse@221c8000 {
		compatible = "qcom,sun-qfprom", "qcom,qfprom";
		reg = <0x0 0x221c8000 0x0 0x1000>;
		#address-cells = <1>;
		#size-cells = <1>;

		gpu_speed_bin: gpu-speed-bin@138 {
			reg = <0x138 0x2>;
			bits = <0 9>;
		};
	};

	gpucc: gpu-cc@3d90000 {
		compatible = "qcom,sm8750-gpucc";
		reg = <0x0 0x03d90000 0x0 0x9800>;

		clocks = <&bi_tcxo_div2>,
			 <&gcc GCC_GPU_GPLL0_CLK_SRC>,
			 <&gcc GCC_GPU_GPLL0_DIV_CLK_SRC>;
		clock-names = "xo",
			      "gpll0",
			      "gpll0_div";

		power-domains = <&rpmhpd RPMHPD_MX>,
				<&rpmhpd RPMHPD_CX>;
		required-opps = <&rpmhpd_opp_low_svs>,
				<&rpmhpd_opp_low_svs>;
		#clock-cells = <1>;
		#reset-cells = <1>;
		#power-domain-cells = <1>;
	};

	gxclkctl: gx-clkctl@3d64000 {
		compatible = "qcom,sm8750-gxclkctl";
		reg = <0x0 0x03d64000 0x0 0x6000>;

		power-domains = <&rpmhpd RPMHPD_GFX>,
				<&rpmhpd RPMHPD_GMXC>,
				<&gpucc GPU_CC_CX_GDSC>;
		#power-domain-cells = <1>;
	};

	adreno_smmu: iommu@3da0000 {
		compatible = "qcom,sm8750-smmu-500", "qcom,adreno-smmu",
			     "qcom,smmu-500", "arm,mmu-500";
		reg = <0x0 0x03da0000 0x0 0x40000>;
		#iommu-cells = <2>;
		#global-interrupts = <1>;
		interrupts = <GIC_SPI 674 IRQ_TYPE_LEVEL_HIGH>,
			     <GIC_SPI 678 IRQ_TYPE_LEVEL_HIGH>,
			     <GIC_SPI 679 IRQ_TYPE_LEVEL_HIGH>,
			     <GIC_SPI 680 IRQ_TYPE_LEVEL_HIGH>,
			     <GIC_SPI 681 IRQ_TYPE_LEVEL_HIGH>,
			     <GIC_SPI 682 IRQ_TYPE_LEVEL_HIGH>,
			     <GIC_SPI 683 IRQ_TYPE_LEVEL_HIGH>,
			     <GIC_SPI 684 IRQ_TYPE_LEVEL_HIGH>,
			     <GIC_SPI 685 IRQ_TYPE_LEVEL_HIGH>,
			     <GIC_SPI 686 IRQ_TYPE_LEVEL_HIGH>,
			     <GIC_SPI 687 IRQ_TYPE_LEVEL_HIGH>,
			     <GIC_SPI 688 IRQ_TYPE_LEVEL_HIGH>,
			     <GIC_SPI 422 IRQ_TYPE_LEVEL_HIGH>,
			     <GIC_SPI 476 IRQ_TYPE_LEVEL_HIGH>,
			     <GIC_SPI 574 IRQ_TYPE_LEVEL_HIGH>,
			     <GIC_SPI 575 IRQ_TYPE_LEVEL_HIGH>,
			     <GIC_SPI 576 IRQ_TYPE_LEVEL_HIGH>,
			     <GIC_SPI 577 IRQ_TYPE_LEVEL_HIGH>,
			     <GIC_SPI 660 IRQ_TYPE_LEVEL_HIGH>,
			     <GIC_SPI 662 IRQ_TYPE_LEVEL_HIGH>,
			     <GIC_SPI 665 IRQ_TYPE_LEVEL_HIGH>,
			     <GIC_SPI 666 IRQ_TYPE_LEVEL_HIGH>,
			     <GIC_SPI 667 IRQ_TYPE_LEVEL_HIGH>,
			     <GIC_SPI 669 IRQ_TYPE_LEVEL_HIGH>,
			     <GIC_SPI 670 IRQ_TYPE_LEVEL_HIGH>,
			     <GIC_SPI 700 IRQ_TYPE_LEVEL_HIGH>;
		clocks = <&gpucc GPU_CC_HLOS1_VOTE_GPU_SMMU_CLK>;
		clock-names = "hlos";
		power-domains = <&gpucc GPU_CC_CX_GDSC>;
		dma-coherent;
	};

	gpu: gpu@3d00000 {
		compatible = "qcom,adreno-44050001", "qcom,adreno";
		reg = <0x0 0x03d00000 0x0 0x60000>,
		      <0x0 0x03d9e000 0x0 0x2000>,
		      <0x0 0x03d61000 0x0 0x800>;
		reg-names = "kgsl_3d0_reg_memory",
			    "cx_mem",
			    "cx_dbgc";

		interrupts = <GIC_SPI 300 IRQ_TYPE_LEVEL_HIGH>;

		iommus = <&adreno_smmu 0 0x0>,
			 <&adreno_smmu 1 0x0>;

		operating-points-v2 = <&gpu_opp_table>;

		nvmem-cells = <&gpu_speed_bin>;
		nvmem-cell-names = "speed_bin";

		qcom,gmu = <&gmu>;
		#cooling-cells = <2>;

		interconnects = <&gem_noc MASTER_GFX3D QCOM_ICC_TAG_ALWAYS
				 &mc_virt SLAVE_EBI1 QCOM_ICC_TAG_ALWAYS>;
		interconnect-names = "gfx-mem";

		/*
		 * Zap shader firmware.
		 *
		 * firmware-name is MANDATORY here, not stylistic. The A830
		 * entry in a6xx_catalog.c has no .zapfw member, so
		 * adreno_zap_shader_load() cannot fall back to the default
		 * "<chip>.zapfw" name and would never find this file.
		 *
		 * Reuses the existing gpu_micro_code_mem (0x9b09a000, 0x2000,
		 * no-map) instead of adding a reserved-memory node: the MDT
		 * needs qcom_mdt_get_size() = 0x1000 (4096 B) for this
		 * image, which is half of what that region already reserves.
		 * Verified against the extracted file -- ELF32/QUALCOMM DSP6,
		 * single PT_LOAD with paddr=0x1000 memsz=0x3b4, entry 0x1000.
		 *
		 * Deliberately NOT namespaced under a "qcom/sm8750/"
		 * subdirectory the way the TB322FC reference tree does, so
		 * the name here matches CONFIG_EXTRA_FIRMWARE exactly. A
		 * subdir would need a matching EXTRA_FIRMWARE_DIR layout
		 * change for no benefit on a single-target board.
		 *
		 * No status property: this is not a device, it is a data
		 * leaf under &gpu, and of_get_available_child_by_name()
		 * finds any node without status (status is only consulted
		 * to reject nodes that say "disabled").
		 *
		 * Risk, recorded on purpose: unlike the -ENODEV path, a
		 * firmware/PAS/MDT error other than -ENODEV aborts the GPU
		 * probe outright. Mitigation -- qcom_pas_is_available()
		 * was already proven true on this device, because the
		 * no-node fallback logged
		 *   "Zap shader not enabled - using SECVID_TRUST_CNTL instead"
		 * which only prints on the ret == -ENODEV branch, and that
		 * branch is only reachable when PAS is available. PAS
		 * absence would have returned -EPROBE_DEFER and killed the
		 * probe, which did not happen.
		 */
		gpu_zap_shader: zap-shader {
			firmware-name = "qcom/gen80000_zap.mbn";
			memory-region = <&gpu_micro_code_mem>;
		};

		gpu_opp_table: gpu-opp-table {
			compatible = "operating-points-v2-adreno",
				    "operating-points-v2";

			opp-1100000000 {
				opp-hz = /bits/ 64 <1100000000>;
				opp-level = <RPMH_REGULATOR_LEVEL_TURBO_L3>;
				opp-peak-kBps = <18597656>;
				opp-supported-hw = <0x6>;
				qcom,opp-acd-level = <0x88295ffd>;
			};

			opp-1050000000 {
				opp-hz = /bits/ 64 <1050000000>;
				opp-level = <RPMH_REGULATOR_LEVEL_TURBO_L1>;
				opp-peak-kBps = <18597656>;
				opp-supported-hw = <0xe>;
				qcom,opp-acd-level = <0xa8295ffd>;
			};

			opp-967000000 {
				opp-hz = /bits/ 64 <967000000>;
				opp-level = <RPMH_REGULATOR_LEVEL_NOM_L1>;
				opp-peak-kBps = <18597656>;
				opp-supported-hw = <0xe>;
				qcom,opp-acd-level = <0x882a5ffd>;
			};

			opp-900000000 {
				opp-hz = /bits/ 64 <900000000>;
				opp-level = <RPMH_REGULATOR_LEVEL_NOM>;
				opp-peak-kBps = <16500000>;
				opp-supported-hw = <0x1e>;
				qcom,opp-acd-level = <0x882a5ffd>;
			};

			opp-832000000 {
				opp-hz = /bits/ 64 <832000000>;
				opp-level = <RPMH_REGULATOR_LEVEL_SVS_L2>;
				opp-peak-kBps = <16500000>;
				opp-supported-hw = <0x1e>;
				qcom,opp-acd-level = <0x882a5ffd>;
			};

			opp-734000000 {
				opp-hz = /bits/ 64 <734000000>;
				opp-level = <RPMH_REGULATOR_LEVEL_SVS_L1>;
				opp-peak-kBps = <12449218>;
				opp-supported-hw = <0x1e>;
				qcom,opp-acd-level = <0xa82a5ffd>;
			};

			opp-660000000 {
				opp-hz = /bits/ 64 <660000000>;
				opp-level = <RPMH_REGULATOR_LEVEL_SVS_L0>;
				opp-peak-kBps = <8171875>;
				opp-supported-hw = <0x1e>;
				qcom,opp-acd-level = <0x882c5ffd>;
			};

			opp-607000000 {
				opp-hz = /bits/ 64 <607000000>;
				opp-level = <RPMH_REGULATOR_LEVEL_SVS>;
				opp-peak-kBps = <8171875>;
				opp-supported-hw = <0x1e>;
				qcom,opp-acd-level = <0xa82e5ffd>;
			};

			opp-525000000 {
				opp-hz = /bits/ 64 <525000000>;
				opp-level = <RPMH_REGULATOR_LEVEL_LOW_SVS_L1>;
				opp-peak-kBps = <6074218>;
				opp-supported-hw = <0x1e>;
				qcom,opp-acd-level = <0xc02e5ffd>;
			};

			opp-443000000 {
				opp-hz = /bits/ 64 <443000000>;
				opp-level = <RPMH_REGULATOR_LEVEL_LOW_SVS>;
				opp-peak-kBps = <6074218>;
				opp-supported-hw = <0x1e>;
				qcom,opp-acd-level = <0xc02e5ffd>;
			};

			opp-389000000 {
				opp-hz = /bits/ 64 <389000000>;
				opp-level = <RPMH_REGULATOR_LEVEL_LOW_SVS_D0>;
				opp-peak-kBps = <6074218>;
				opp-supported-hw = <0x1e>;
				qcom,opp-acd-level = <0xc8285ffd>;
			};

			opp-342000000 {
				opp-hz = /bits/ 64 <342000000>;
				opp-level = <RPMH_REGULATOR_LEVEL_LOW_SVS_D1>;
				opp-peak-kBps = <5285156>;
				opp-supported-hw = <0x1e>;
			};

			opp-222000000 {
				opp-hz = /bits/ 64 <222000000>;
				opp-level = <RPMH_REGULATOR_LEVEL_LOW_SVS_D2>;
				opp-peak-kBps = <2136718>;
				opp-supported-hw = <0x1e>;
			};

			opp-160000000 {
				opp-hz = /bits/ 64 <160000000>;
				opp-level = <RPMH_REGULATOR_LEVEL_LOW_SVS_D3>;
				opp-peak-kBps = <2136718>;
				opp-supported-hw = <0x1e>;
			};
		};
	};

	gmu: gmu@3d37000 {
		compatible = "qcom,adreno-gmu-830.1", "qcom,adreno-gmu";

		reg = <0x0 0x03d37000 0x0 0x68000>;
		reg-names = "gmu";

		interrupts = <GIC_SPI 304 IRQ_TYPE_LEVEL_HIGH>,
			     <GIC_SPI 305 IRQ_TYPE_LEVEL_HIGH>;
		interrupt-names = "hfi", "gmu";

		/*
		 * 5 个（照参考）。a6xx_gmu_clocks_probe() 走
		 * devm_clk_bulk_get_all()，只按名字取 "gmu"/"hub"，
		 * 上游 glymur.dtsi 多写的 "rscc" 对本轮无行为差异。
		 * stock 的第二段 0x3d40000/0x10000 是 gmu_ao_blk_dec0，
		 * 主线 a6xx_gmu_get_mmio() 只取 IORESOURCE_MEM index 0，
		 * 故 reg-names 只留 "gmu"。
		 */
		clocks = <&gpucc GPU_CC_AHB_CLK>,
			 <&gpucc GPU_CC_CX_GMU_CLK>,
			 <&gpucc GPU_CC_CXO_CLK>,
			 <&gcc GCC_GPU_GEMNOC_GFX_CLK>,
			 <&gpucc GPU_CC_HUB_CX_INT_CLK>;
		clock-names = "ahb",
			      "gmu",
			      "cxo",
			      "memnoc",
			      "hub";

		power-domains = <&gpucc GPU_CC_CX_GDSC>,
				<&gxclkctl GX_CLKCTL_GX_GDSC>;
		power-domain-names = "cx",
				     "gx";

		iommus = <&adreno_smmu 5 0x0>;

		qcom,qmp = <&aoss_qmp>;

		operating-points-v2 = <&gmu_opp_table>;

		gmu_opp_table: gmu-opp-table {
			compatible = "operating-points-v2";

			opp-500000000 {
				opp-hz = /bits/ 64 <500000000>;
				opp-level = <RPMH_REGULATOR_LEVEL_LOW_SVS>;
			};

			opp-650000000 {
				opp-hz = /bits/ 64 <650000000>;
				opp-level = <RPMH_REGULATOR_LEVEL_SVS>;
			};

			opp-687500000 {
				opp-hz = /bits/ 64 <687500000>;
				opp-level = <RPMH_REGULATOR_LEVEL_SVS_L1>;
			};
		};
	};
};

/*
 * GPU 被动散热：8 个 gpussN-thermal 加 105°C passive trip，
 * cooling-device 挂 &gpu（#cooling-cells = <2>，已在上面声明）。
 *
 * 这 8 个 zone 在 sm8750.dtsi 里已存在且已带 thermal-sensors + hot(120C)/
 * critical(125C) trips，这里只叠加 passive trip。dtc 对无 unit-address 的
 * 同名子节点做合并，trip-point0 / gpussN-critical 不会被覆盖掉。
 * THERMAL_NO_LIMIT/THERMAL_NO_LIMIT = 不真正改频率，本轮只建立拓扑。
 */
&{/thermal-zones} {
	gpuss0-thermal {
		polling-delay-passive = <100>;

		trips {
			gpuss0_passive: gpuss0-passive {
				temperature = <105000>;
				hysteresis = <5000>;
				type = "passive";
			};
		};

		cooling-maps {
			map0 {
				trip = <&gpuss0_passive>;
				cooling-device = <&gpu THERMAL_NO_LIMIT THERMAL_NO_LIMIT>;
			};
		};
	};

	gpuss1-thermal {
		polling-delay-passive = <100>;

		trips {
			gpuss1_passive: gpuss1-passive {
				temperature = <105000>;
				hysteresis = <5000>;
				type = "passive";
			};
		};

		cooling-maps {
			map0 {
				trip = <&gpuss1_passive>;
				cooling-device = <&gpu THERMAL_NO_LIMIT THERMAL_NO_LIMIT>;
			};
		};
	};

	gpuss2-thermal {
		polling-delay-passive = <100>;

		trips {
			gpuss2_passive: gpuss2-passive {
				temperature = <105000>;
				hysteresis = <5000>;
				type = "passive";
			};
		};

		cooling-maps {
			map0 {
				trip = <&gpuss2_passive>;
				cooling-device = <&gpu THERMAL_NO_LIMIT THERMAL_NO_LIMIT>;
			};
		};
	};

	gpuss3-thermal {
		polling-delay-passive = <100>;

		trips {
			gpuss3_passive: gpuss3-passive {
				temperature = <105000>;
				hysteresis = <5000>;
				type = "passive";
			};
		};

		cooling-maps {
			map0 {
				trip = <&gpuss3_passive>;
				cooling-device = <&gpu THERMAL_NO_LIMIT THERMAL_NO_LIMIT>;
			};
		};
	};

	gpuss4-thermal {
		polling-delay-passive = <100>;

		trips {
			gpuss4_passive: gpuss4-passive {
				temperature = <105000>;
				hysteresis = <5000>;
				type = "passive";
			};
		};

		cooling-maps {
			map0 {
				trip = <&gpuss4_passive>;
				cooling-device = <&gpu THERMAL_NO_LIMIT THERMAL_NO_LIMIT>;
			};
		};
	};

	gpuss5-thermal {
		polling-delay-passive = <100>;

		trips {
			gpuss5_passive: gpuss5-passive {
				temperature = <105000>;
				hysteresis = <5000>;
				type = "passive";
			};
		};

		cooling-maps {
			map0 {
				trip = <&gpuss5_passive>;
				cooling-device = <&gpu THERMAL_NO_LIMIT THERMAL_NO_LIMIT>;
			};
		};
	};

	gpuss6-thermal {
		polling-delay-passive = <100>;

		trips {
			gpuss6_passive: gpuss6-passive {
				temperature = <105000>;
				hysteresis = <5000>;
				type = "passive";
			};
		};

		cooling-maps {
			map0 {
				trip = <&gpuss6_passive>;
				cooling-device = <&gpu THERMAL_NO_LIMIT THERMAL_NO_LIMIT>;
			};
		};
	};

	gpuss7-thermal {
		polling-delay-passive = <100>;

		trips {
			gpuss7_passive: gpuss7-passive {
				temperature = <105000>;
				hysteresis = <5000>;
				type = "passive";
			};
		};

		cooling-maps {
			map0 {
				trip = <&gpuss7_passive>;
				cooling-device = <&gpu THERMAL_NO_LIMIT THERMAL_NO_LIMIT>;
			};
		};
	};
};

/*
 * ── 扬声器数字通路（LPASS 第二接口 BE）──
 *
 * 结构逐字照抄已验证出声的 sm8750-lenovo-elden.dts:1981。
 * #address-cells/#size-cells 是必需的：dai@12 是带 reg 的子节点，
 * 缺了 dtc 会报 "ranged but no #address-cells"。
 *
 * 端口选 SECONDARY_MI2S_RX(18) 而非 SECONDARY_TDM_RX_0(40)：照抄 elden，
 * 且 stock 的 qcom,sec-mi2s-gpios 也指向同一组 pad（gpio121/123/124）。
 * 若无声再按 docs「回退链」切 TDM_RX_0。
 */
&q6apmbedai {
	#address-cells = <1>;
	#size-cells = <0>;

	dai@12 {
		reg = <SECONDARY_MI2S_RX>;
		clocks = <&q6prmcc LPASS_CLK_ID_SEC_MI2S_IBIT LPASS_CLK_ATTRIBUTE_COUPLE_NO>;
		clock-names = "bclk";
	};
};

/*
 * ── 绕过 PDR：直接注册 q6apm / q6prm ──
 *
 * 主线 sm8750.dtsi:2354/2372 给 service@1(q6apm)/service@2(q6prm) 都带了
 * qcom,protection-domain = "avs/audio", "msm/adsp/audio_pd"。后果见
 * drivers/soc/qcom/apr.c:
 *
 *   of_register_apr_devices(dev, NULL)   ← apr_probe:643，svc_path 传 NULL
 *     of_property_read_string_index(node, "qcom,protection-domain", 1, ...)
 *     if (svc_path) {...} else {
 *         if (ret == 0) continue;        ← apr.c:549：有 PD 属性就跳过
 *     }
 *
 * 于是 probe 阶段两个 service 都不注册，必须等 PDR 回调
 * apr_pd_status(SERVREG_SERVICE_STATE_UP, "msm/adsp/audio_pd")。实测
 * （2026-10-03，dada + 原厂 adsp.mdt）该回调从未触发：/sys/bus/aprbus/devices/
 * 恒为空，dmesg 里 pdr_interface.c:321 的 "PDR: Indication received" 从未出现，
 * ADSP stop/start 重跑 apr_probe 结果相同（详见 docs/audio-fix.md 诊断记录）。
 * 下游连锁：aprbus 空 → q6apm/q6prm 不 probe → bedais 与 clock-controller 不
 * 创建 → q6apm-lpass-dais 无设备 → snd-sc8280xp 卡在
 * "Secondary MI2S: error getting cpu dai name"（common.c:268），永久 deferred。
 *
 * 删掉该属性后：
 *   of_apr_add_pd_lookups(): index 0 读取失败 → continue（不 return，probe 不失败）
 *   of_register_apr_devices(NULL): ret != 0 → 不 skip → apr_add_device 直接注册
 *
 * 两个必须一起删：q6prmcc 的 phandle 被上面 dai@12 的 clocks 引用，
 * service@2 不注册则该 phandle 悬空，dai@12 会 probe 失败。
 *
 * 风险：若 ADSP 的 audio_pd 确实未 UP，q6apm 发 GPR 包会超时 —— 但原厂
 * adsp.mdt 与 Android 共用，audio_pd 应开机即起。
 */
&q6apm {
	/delete-property/ qcom,protection-domain;
};

&q6prm {
	/delete-property/ qcom,protection-domain;
};

/*
 * ── 声卡 ──
 *
 * 关键点（docs/audio-fix.md 架构结论 1-5）：
 *  - model 必须 = "Xiaomi-dada"：它决定拓扑文件路径
 *    qcom/sm8750/Xiaomi-dada-tplg.bin（topology.c:1422 拼
 *    "qcom/%s/%s-tplg.bin", card->driver_name, card->name，
 *    driver_name 由 sc8280xp.c:554 固定为 "sm8750"）。
 *  - FE 不在这里，由 .tplg.bin 提供；这里只写 BE + 两颗 codec。
 *  - 不写 dai-tdm-slot：对本链路它是死配置（调用点 sc8280xp.c:142 只在
 *    case PRIMARY_TDM_RX_0...QUINARY_TDM_TX_7 分支，MI2S BE 不进那条），
 *    写了也不会被解析；若改用 SECONDARY_TDM_RX_0 则会变成硬失败
 *    （q6i2s_ops / cs35l43_ops 都没有 set_tdm_slot，common.c:136 返回非 0
 *    → BE init 失败 → 声卡注册不了）。立体声不需要它，见 audio-fix.md
 *    「架构结论 5」与「立体声槽位分离（build #28）」。
 *  - audio-routing 的 source 名 = sound-name-prefix + " " + codec 的
 *    output widget（cs35l43.c:905 SND_SOC_DAPM_OUTPUT("SPK")），
 *    见 soc-dapm.c:3106 "plus space"，故写作 "B SPK"/"T SPK"。
 */
/ {
	/*
	 * WCD9395（build #34）：dada 所有 PDM 麦克风的 MICBIAS 供电方。
	 * P3 全部 DMIC 对录音为纯数字零的根因：mainline 无 wcd939x →
	 * "MIC BIASx"/"VA MIC BIASx" 不存在 → 麦无电。DAPM 路由
	 * "VA DMICn" ← bias 由下方 sound 节点给出（同 sm8750-mtp.dts:127-135）。
	 * 节点照抄 sm8750-mtp.dts:32-60：
	 *  - 复位脚 gpio101：vendor references/.../sun-pinctrl.dtsi:638
	 *    （wcd939x_reset_active，与 mtp 同）；ACTIVE_LOW 使
	 *    wcd939x.c:3178 GPIOD_OUT_LOW 初值 = 物理高（非复位）。
	 *  - micbias 2750mV：stock android.dts qcom,cdc-micbias*-mv = 0xabe。
	 *  - 电压三轨与 stock cdc-vdd-* 请求吻合（1.8V/1.2V），BOB1 范围取 mtp。
	 *  - mode-switch/orientation-switch/port 略去：CONFIG_TYPEC=n 时
	 *    wcd939x.c 的 typec 段整段 #if 掉，且 dada 不走 USB 模拟音频。
	 */
	wcd939x: audio-codec {
		compatible = "qcom,wcd9395-codec", "qcom,wcd9390-codec";

		pinctrl-0 = <&wcd_default>;
		pinctrl-names = "default";

		qcom,micbias1-microvolt = <2750000>;
		qcom,micbias2-microvolt = <2750000>;
		qcom,micbias3-microvolt = <2750000>;
		qcom,micbias4-microvolt = <2750000>;
		qcom,mbhc-buttons-vthreshold-microvolt = <75000 150000 237000 500000 500000 500000 500000 500000>;
		qcom,mbhc-headset-vthreshold-microvolt = <1700000>;
		qcom,mbhc-headphone-vthreshold-microvolt = <50000>;
		qcom,rx-device = <&wcd_rx>;
		qcom,tx-device = <&wcd_tx>;

		reset-gpios = <&tlmm 101 GPIO_ACTIVE_LOW>;

		vdd-buck-supply = <&vreg_l15b_1p8>;
		vdd-rxtx-supply = <&vreg_l15b_1p8>;
		vdd-io-supply = <&vreg_l15b_1p8>;
		vdd-mic-bias-supply = <&vreg_bob1>;
		vdd-px-supply = <&vreg_l2i_1p2>;

		#sound-dai-cells = <1>;
	};

	sound {
		compatible = "qcom,sm8750-sndcard", "qcom,sm8450-sndcard";
		model = "Xiaomi-dada";
		pinctrl-names = "default";
		pinctrl-0 = <&secondary_mi2s_default>;

		widgets = "Speaker", "Bottom Speaker",
			  "Speaker", "Top Speaker";
		/*
		 * route A（VA/PDM，build #29-36）：LPASS DMIC 引脚 → VA macro →
		 * VA_CODEC_DMA_TX_0。pad 层实测三对 clk 都出、data 全静态 ⇒
		 * build #37 加 route B：WCD TX → TX_CODEC_DMA_TX_3（DTS
		 * wcd-capture-dai-link + topology device120）。三条子路径全覆盖，
		 * 上机后用 amixer 走查（widget 名逐一对照 wcd939x.c /
		 * lpass-tx-macro.c 源码，soc-core.c:2107 加路由失败=声卡 probe
		 * 失败，名字错一个整卡就没了）：
		 *  B1 AMIC（模拟麦，已打通）：AMICy ← MIC BIASx（bias 映射抄
		 *     stock android.dts:19221），ADCx MUX → ADCx_OUTPUT →
		 *     TX SWR_INPUT0-3（kaanapali-mtp.dts:1223 端口映射：
		 *     WCD9395 TX Port1 ADC1-4 ⇔ SWR2 Port2 = INPUT0-3；
		 *     qcom,tx-port-mapping=<2 2 3 4> 见 :2402）。
		 *     底部麦生产链 = AMIC4 → ADC2 → INPUT1（2026-10-08 #39：
		 *     ADC1 通道锁死撞轨振荡，死线 AMIC2 亦出撞轨 ⇒
		 *     CH1/ADC1 共用级故障；ADC2 同 pad 实测干净，mic-defaults
		 *     已切 ADC2，INPUT0←ADC1 路由保留作回退）。
		 *  B2/B3 路由 build #39 摘除：B2（WCD DMICn → INPUT4-11）
		 *     实测恒静默无数据；B3（LPASS TX DMICn ← BIASx）数据干净
		 *     但非生产链。未删的路由继续跑在声卡 probe 的
		 *     soc-core.c:2107 校验上，删掉即缩小爆炸半径。
		 */
		audio-routing = "Bottom Speaker", "B SPK",
				"Top Speaker", "T SPK",
				"VA DMIC0", "MIC BIAS3",
				"VA DMIC1", "MIC BIAS3",
				"VA DMIC2", "MIC BIAS1",
				"VA DMIC3", "MIC BIAS1",
				"VA DMIC0", "VA MIC BIAS3",
				"VA DMIC1", "VA MIC BIAS3",
				"VA DMIC2", "VA MIC BIAS1",
				"VA DMIC3", "VA MIC BIAS1",
				"AMIC1", "MIC BIAS1",
				"AMIC2", "MIC BIAS2",
				"AMIC3", "MIC BIAS4",
				"AMIC4", "MIC BIAS4",
				"AMIC5", "MIC BIAS3",
				"TX SWR_INPUT0", "ADC1_OUTPUT",
				"TX SWR_INPUT1", "ADC2_OUTPUT",
				"TX SWR_INPUT2", "ADC3_OUTPUT",
				"TX SWR_INPUT3", "ADC4_OUTPUT";

		secondary-mi2s-dai-link {
			link-name = "Secondary MI2S";

			cpu {
				sound-dai = <&q6apmbedai SECONDARY_MI2S_RX>;
			};

			codec {
				sound-dai = <&cs35l43_0>, <&cs35l43_1>;
			};

			platform {
				sound-dai = <&q6apm>;
			};
		};

		/*
		 * 麦克风 route A（build #29）：DMIC → VA macro → VA_CODEC_DMA_TX_0。
		 * 照抄 sm8750-mtp.dts 的 va-dai-link（同 SoC 同 codec 组合）。
		 * BE 侧 VA_CODEC_DMA_TX_0 属 codec-dma 类，不需要 q6apmbedai 的
		 * dai@ 子节点（那只有 MI2S/TDM BE 要 bclk 时才写，见上面 dai@12）。
		 * FE 由 topology.m4 提供（P2），本 build 只让声卡枚举出 capture 链路。
		 * build #34 起此路仍走 VA；WCD link 仅为把 wcd939x 组件挂进声卡，
		 * 让 MIC BIAS 供 DAPM 使用（见上方 audio-routing）。
		 */
		va-capture-dai-link {
			link-name = "VA Capture";

			cpu {
				sound-dai = <&q6apmbedai VA_CODEC_DMA_TX_0>;
			};

			codec {
				sound-dai = <&lpass_vamacro 0>;
			};

			platform {
				sound-dai = <&q6apm>;
			};
		};

		/*
		 * build #34：照抄 sm8750-mtp.dts:139-176 的 wcd-playback/
		 * wcd-capture。本机不使用这两条链路收发音频（播放=cs35l43，
		 * 录音=VA Capture），加它们的唯一目的是把 wcd939x（及 swr1/2、
		 * rx/tx macro）组件 bind 进本声卡 —— DAPM 的 "MIC BIASx"/
		 * "VA MIC BIASx" supply widget 属 wcd939x.c:2675-2706，组件不
		 * 入卡则路由两端不共图，麦 bias 永远不会上电。
		 * 若 wcd 探测失败本卡会整体 EPROBE_DEFER（表现为无声卡），
		 * 属预期失败模式，回退即可。
		 */
		wcd-playback-dai-link {
			link-name = "WCD Playback";

			codec {
				sound-dai = <&wcd939x 0>, <&swr1 0>, <&lpass_rxmacro 0>;
			};

			cpu {
				sound-dai = <&q6apmbedai RX_CODEC_DMA_RX_0>;
			};

			platform {
				sound-dai = <&q6apm>;
			};
		};

		wcd-capture-dai-link {
			link-name = "WCD Capture";

			codec {
				sound-dai = <&wcd939x 1>, <&swr2 0>, <&lpass_txmacro 0>;
			};

			cpu {
				sound-dai = <&q6apmbedai TX_CODEC_DMA_TX_3>;
			};

			platform {
				sound-dai = <&q6apm>;
			};
		};
	};
};

/*
 * DMIC 引脚与采样率（同 sm8750-mtp.dts:978-983）：
 *  - dmic01/dmic23 LPI pinctrl 已在 sm8750.dtsi 定义（:2659/:2675）；
 *    stock 另接了 cdc-dmic45（android.dts:19215），主线没有 —— dmic45_default
 *    在下方 &lpass_tlmm 补齐（必须挂在控制器节点下：pinctrl 核心靠向上遍历
 *    state 节点父链找控制器，devicetree.c:126-159，挂在设备节点下会被静默跳过）。
 *  - qcom,dmic-sample-rate：4.8MHz（build #36 修正）。#35 曾改 600kHz，依据
 *    是 stock 的 `qcom,va-dmic-clk-div-factor = <0x10...>`（android.dts:18821）
 *    —— 该属性在 vendor 内核源码零引用（死属性），stock dada DTS 根本没有
 *    qcom,dmic-sample-rate ⇒ vendor 驱动走 "dt entry missing" 分支
 *    （lpass-va-macro.c:1477）→ VA_MACRO_CLK_DIV_2 → 9.6M/2 = **4.8MHz**。
 *    in-tree sm8750-mtp.dts:983 同为 <4800000>（DMIC 在 mainline-status
 *    标 6.17 已支持的测试板）。#35 的 600kHz 落在多数手机 DMIC 规格
 *    （~1MHz 起）之外 ⇒ 麦静默。4800000 → div=2 → VA_MACRO_CLK_DIV_2=0，
 *    录音时 CDC_VA_TOP_CSR_DMIC0_CTL(0x084) = 0x01（EN|SEL0）。
 */
&lpass_tlmm {
	/* stock 的 cdc-dmic45（DMIC4/5 对）走 LPI 函数 dmic3_clk/dmic3_data（gpio12/13） */
	dmic45_default: dmic45-default-state {
		clk-pins {
			pins = "gpio12";
			function = "dmic3_clk";
			drive-strength = <8>;
			output-high;
		};
		data-pins {
			pins = "gpio13";
			function = "dmic3_data";
			drive-strength = <8>;
			input-enable;
		};
	};
};

&lpass_vamacro {
	pinctrl-names = "default";
	pinctrl-0 = <&dmic01_default>, <&dmic23_default>, <&dmic45_default>;
	qcom,dmic-sample-rate = <4800000>;
};

/*
 * WCD9395 SoundWire 从设备（build #34，照抄 sm8750-mtp.dts:1247-1283）。
 * sm8750.dtsi 里 swr1(label RX)@6ad0000 / swr2(label TX)@7630000 默认
 * status=disabled，必须 okay。stock 的 slave 挂点一致：android.dts 的
 * wcd939x-tx-slave swrm-io-base=0x7630000、rx-slave=0x6ad0000。
 * compatible "sdw20217010e00" = SDW_SLAVE_ID(0x0217,0x010E,0x00)，由
 * SoundWire 枚举匹配 wcd939x-sdw.c；port-mapping 供 wcd939x-sdw.c:1352 解析。
 */
&swr1 {
	status = "okay";

	/* WCD9395 RX */
	wcd_rx: codec@0,4 {
		compatible = "sdw20217010e00";
		reg = <0 4>;
		qcom,rx-port-mapping = <1 2 3 4 5 9>;
	};
};

&swr2 {
	status = "okay";

	/* WCD9395 TX */
	wcd_tx: codec@0,3 {
		compatible = "sdw20217010e00";
		reg = <0 3>;
		qcom,tx-port-mapping = <2 2 3 4>;
	};
};

/* wcd939x 复位脚（wcd939x.c:3178 devm_gpiod_get 必需，缺了直接 probe 失败）。
 * 状态照抄 mtp wcd_default（sm8750-mtp.dts:1350）；gpio101 已由 vendor
 * sun-pinctrl.dtsi:638 确认为 dada 的 WCD reset。挂 &tlmm 下即可（普通
 * tlmm pinctrl，与 LPI 无关）。 */
&tlmm {
	wcd_default: wcd-reset-n-active-state {
		pins = "gpio101";
		function = "gpio";
		drive-strength = <16>;
		bias-disable;
		output-low;
	};
};

/* MCA board wiring: vendor DTBO fragments 47/48, preserved source evidence. */
&i2c5 {
	/*
	 * 电荷泵 SC8585（mca 的 sc8581.c 驱动，匹配 "sc8585_master"）。
	 * 出处：厂商 dtbo_a.img -> fragment@47（target = qupv3_se5_i2c，即本 i2c5）
	 *   cp-int       = <&tlmm 0x44 0>  -> GPIO 68
	 *   cp-nlpm-gpio = <&tlmm 0x6e 0>  -> GPIO 110
	 * 厂商原节点没有 pinctrl 之外的额外依赖；此处未带 pinctrl，
	 * 若 nlpm 引脚不通再补 pinmux。
	 */
	sc8585_master@6e {
		compatible = "sc8585_master";
		reg = <0x6e>;
		status = "okay";
		ic_role = <0>;
		cp-int = <&tlmm 68 0>;
		cp-nlpm-gpio = <&tlmm 110 0>;
		bat-ovp-threshold = <0x125c>;
		bat-ovp-alarm-threshold = <0x122a>;
		bus-ovp-threshold = <0x5208 0x2ee0 0x1770>;
		usb-ovp-threshold = <0x5208 0x36b0 0x1d4c>;
		bus-ocp-threshold = <0x1388 0x157c 0x1388>;
		wpc-ovp-threshold = <0x5208>;
		out-ovp-threshold = <0x1388>;
		pmid2-uvp-threshold = <0x64>;
		pmid2-ovp-threshold = <0x258>;
	};

};



#include "sm8750-xiaomi-dada-charging.dtsi"

/* MCA's auxiliary transport needs a PMIC GLINK parent. The generic fallback
 * selects the ADSP service used by SM8750. Keep USB roles fixed in each build.
 */
/ {
	pmic-glink {
		compatible = "qcom,sm8750-pmic-glink",
			     "qcom,sm8550-pmic-glink",
			     "qcom,pmic-glink";
		#address-cells = <1>;
		#size-cells = <0>;
	};
};
